VERSION "..\..\trunk\components\winTestMT\code\canApi\dbcFiles\canBus_02.dbc, created by Octave and generateRandomDbc.m on 21-Feb-2017"

NS_ :

BS_:

BU_: ECU

BO_ 90 frame_90: 8 Vector__XXX
  SG_ checksum_1_8 : 0|8@1+ (1.0,0.0) [0.0|255.0] "" ECU
  SG_ sig_16_36 : 16|36@1+ (1.0000000000000007E-7,-3162.2776601683795) [-3162.2776601683795|3709.670013231626] "kWh" ECU
  SG_ sig_15_7 : 15|7@0- (100.0,3162.2776601683795) [-3237.7223398316205|9362.27766016838] "A" ECU
  SG_ sig_8_1 : 8|1@1+ (1.0,0.0) [0.0|1.0] "" ECU
  SG_ sig_52_10 : 52|10@1+ (1.0000000000000005E-4,0.0) [0.0|0.10220000000000004] "V" ECU

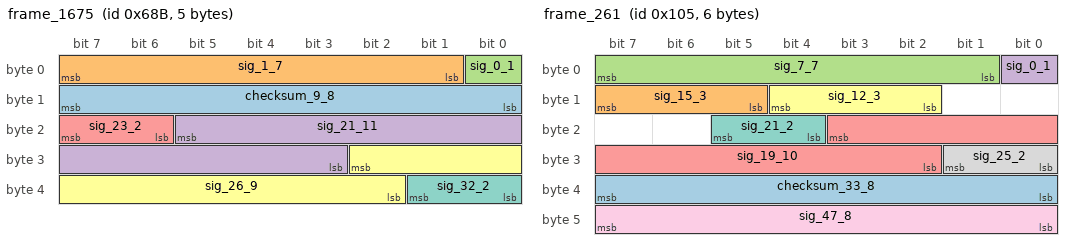
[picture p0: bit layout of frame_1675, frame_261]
BO_ 1675 frame_1675: 5 Vector__XXX
  SG_ checksum_9_8 : 15|8@0+ (1.0,0.0) [0.0|255.0] "" ECU
  SG_ sig_1_7 : 1|7@1+ (0.010000000000000002,0.31622776601683794) [0.31622776601683794|1.5762277660168382] "kWh" ECU
  SG_ sig_0_1 : 0|1@1+ (1.0,0.0) [0.0|1.0] "" ECU
  SG_ sig_21_11 : 21|11@0- (100.0,-31622.776601683792) [-134022.77660168378|70577.22339831622] "A" ECU
  SG_ sig_23_2 : 23|2@0+ (1.0,0.0) [0.0|3.0] "" ECU
  SG_ sig_26_9 : 26|9@0- (1.0000000000000005E-4,0.03162277660168379) [0.00602277660168378|0.057022776601683804] "A" ECU
  SG_ sig_32_2 : 32|2@1+ (1.0,0.0) [0.0|3.0] "" ECU

BO_ 261 frame_261: 6 Vector__XXX
  SG_ checksum_33_8 : 39|8@0+ (1.0,0.0) [0.0|255.0] "" ECU
  SG_ sig_15_3 : 15|3@0+ (1.0,0.0) [0.0|6.0] "" ECU
  SG_ sig_7_7 : 7|7@0+ (1.0,0.0) [0.0|126.0] "" ECU
  SG_ sig_0_1 : 0|1@0+ (1.0,0.0) [0.0|1.0] "" ECU
  SG_ sig_19_10 : 19|10@0+ (1.0000000000000006E-5,0.0031622776601683794) [0.0031622776601683794|0.013382277660168387] "A" ECU
  SG_ sig_12_3 : 12|3@0+ (1.0,0.0) [0.0|6.0] "" ECU
  SG_ sig_21_2 : 21|2@0+ (1.0,0.0) [0.0|3.0] "" ECU
  SG_ sig_25_2 : 25|2@0+ (1.0,0.0) [0.0|3.0] "" ECU
  SG_ sig_47_8 : 47|8@0+ (1.0000000000000005E-4,0.0) [0.0|0.025400000000000013] "W" ECU

BO_ 660 frame_660: 4 Vector__XXX
  SG_ checksum_9_8 : 8|8@1+ (1.0,0.0) [0.0|255.0] "" ECU
  SG_ sig_0_8 : 0|8@1+ (1.0000000000000007E-7,3.162277660168379E-6) [3.162277660168379E-6|2.85622776601684E-5] "kWh" ECU
  SG_ sig_17_14 : 17|14@1+ (1.0000000000000006E-5,0.0) [0.0|0.1638200000000001] "s" ECU
  SG_ sig_16_1 : 16|1@1+ (1.0,0.0) [0.0|1.0] "" ECU
  SG_ sig_31_1 : 31|1@1+ (1.0,0.0) [0.0|1.0] "" ECU

BO_ 1074 frame_1074: 6 Vector__XXX
  SG_ checksum_25_8 : 31|8@0+ (1.0,0.0) [0.0|255.0] "" ECU
  SG_ sig_7_22 : 7|22@0+ (1.0000000000000006E-6,0.0) [0.0|4.194302000000002] "V" ECU
  SG_ sig_17_2 : 17|2@0- (1.0,0.0) [-2.0|1.0] "" ECU
  SG_ sig_37_14 : 37|14@0+ (0.010000000000000002,-31.622776601683793) [-31.622776601683793|132.19722339831623] "A" ECU
  SG_ sig_39_2 : 39|2@0+ (1.0,0.0) [0.0|3.0] "" ECU

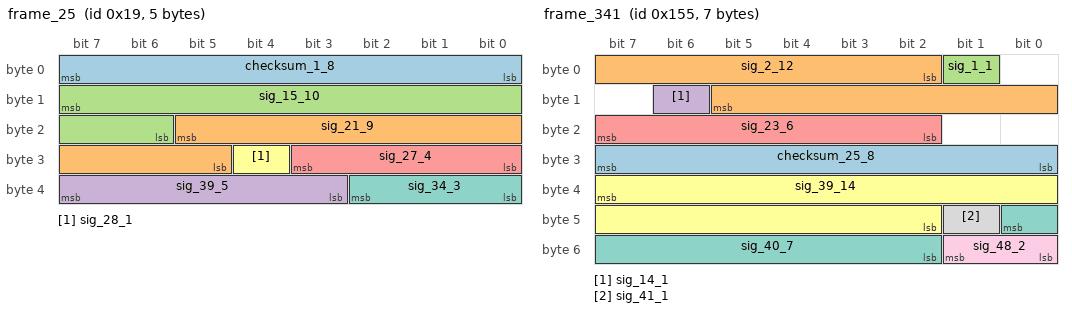
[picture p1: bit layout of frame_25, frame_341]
BO_ 25 frame_25: 5 ECU
  SG_ checksum_1_8 : 7|8@0+ (1.0,0.0) [0.0|255.0] "" Vector__XXX
  SG_ sig_21_9 : 21|9@0+ (1.0,0.0) [0.0|510.0] "" Vector__XXX
  SG_ sig_15_10 : 15|10@0- (1.0,-316.22776601683796) [-828.2277660168379|193.77223398316204] "m/s^2" Vector__XXX
  SG_ sig_39_5 : 39|5@0- (1.0,0.0) [-16.0|14.0] "" Vector__XXX
  SG_ sig_27_4 : 27|4@0- (100.0,316.22776601683796) [-483.77223398316204|916.2277660168379] "A" Vector__XXX
  SG_ sig_28_1 : 28|1@0+ (1.0,0.0) [0.0|1.0] "" Vector__XXX
  SG_ sig_34_3 : 34|3@0+ (1.0,0.0) [0.0|6.0] "" Vector__XXX

BO_ 1747 frame_1747: 8 Vector__XXX
  SG_ checksum_17_8 : 23|8@0+ (1.0,0.0) [0.0|255.0] "" ECU
  SG_ sig_5_14 : 5|14@0+ (1.0,0.0) [0.0|16382.0] "" ECU
  SG_ sig_6_2 : 6|2@1+ (1.0,0.0) [0.0|3.0] "" ECU
  SG_ sig_26_28 : 26|28@0- (1.0000000000000006E-6,31.622776601683793) [-102.59495139831628|165.84050260168388] "m/s^2" ECU
  SG_ sig_31_5 : 31|5@0+ (1.0,0.0) [0.0|30.0] "" ECU
  SG_ sig_62_7 : 62|7@0- (1000.0,-31622.776601683792) [-95622.77660168378|30377.223398316208] "kWh" ECU

BO_ 1641 frame_1641: 5 ECU
  SG_ checksum_25_8 : 31|8@0+ (1.0,0.0) [0.0|255.0] "" Vector__XXX
  SG_ sig_5_15 : 5|15@1+ (1.0000000000000007E-7,0.0) [0.0|0.0032766000000000023] "s" Vector__XXX
  SG_ sig_4_5 : 4|5@0+ (1.0000000000000005E-4,0.0) [0.0|0.0030000000000000014] "A" Vector__XXX
  SG_ sig_23_1 : 23|1@0+ (1.0,0.0) [0.0|1.0] "" Vector__XXX
  SG_ sig_32_8 : 32|8@1- (1.0000000000000005E-4,0.0031622776601683794) [-0.009637722339831626|0.015762277660168383] "A" Vector__XXX

BO_ 786 frame_786: 4 Vector__XXX
  SG_ checksum_1_8 : 7|8@0+ (1.0,0.0) [0.0|255.0] "" ECU
  SG_ sig_20_9 : 20|9@0+ (1.0000000000000006E-5,0.0031622776601683794) [0.0031622776601683794|0.008262277660168382] "km/h" ECU
  SG_ sig_15_8 : 15|8@0- (1.0,0.0) [-128.0|126.0] "" ECU
  SG_ sig_22_2 : 22|2@0- (1.0,0.0) [-2.0|1.0] "" ECU
  SG_ sig_23_1 : 23|1@0+ (1.0,0.0) [0.0|1.0] "" ECU
  SG_ sig_27_4 : 27|4@0- (0.0010000000000000002,0.0031622776601683794) [-0.004837722339831622|0.009162277660168382] "A" ECU

BO_ 341 frame_341: 7 Vector__XXX
  SG_ checksum_25_8 : 24|8@1+ (1.0,0.0) [0.0|255.0] "" ECU
  SG_ sig_2_12 : 2|12@1- (1.0000000000000009E-9,-3.162277660168379E-6) [-5.210277660168381E-6|-1.1162776601683775E-6] "W" ECU
  SG_ sig_1_1 : 1|1@0+ (1.0,0.0) [0.0|1.0] "" ECU
  SG_ sig_14_1 : 14|1@0+ (1.0,0.0) [0.0|1.0] "" ECU
  SG_ sig_23_6 : 23|6@0- (1.0000000000000005E-4,0.0) [-0.0032000000000000015|0.0030000000000000014] "km/h" ECU
  SG_ sig_39_14 : 39|14@0- (1.0000000000000005E-4,-0.31622776601683794) [-1.1354277660168384|0.5027722339831624] "kWh" ECU
  SG_ sig_40_7 : 40|7@0- (1.0,0.0) [-64.0|62.0] "" ECU
  SG_ sig_41_1 : 41|1@0+ (1.0,0.0) [0.0|1.0] "" ECU
  SG_ sig_48_2 : 48|2@1- (1.0,0.0) [-2.0|1.0] "" ECU

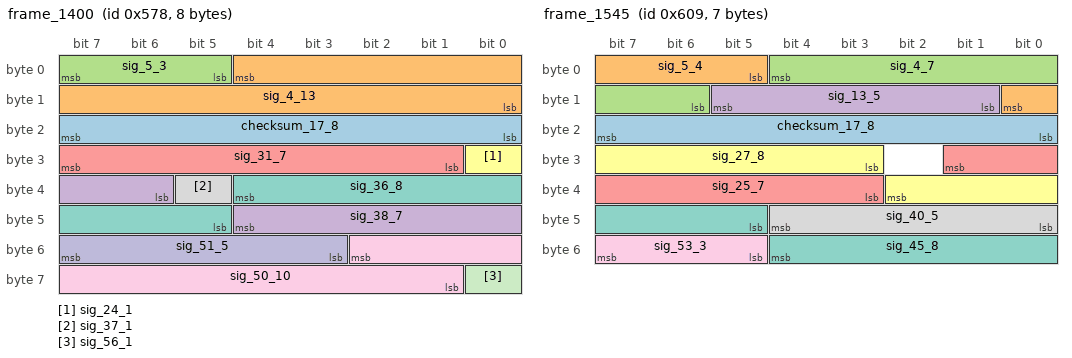
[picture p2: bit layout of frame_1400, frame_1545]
BO_ 1400 frame_1400: 8 Vector__XXX
  SG_ checksum_17_8 : 16|8@1+ (1.0,0.0) [0.0|255.0] "" ECU
  SG_ sig_4_13 : 4|13@0+ (1.0,0.0) [0.0|8190.0] "" ECU
  SG_ sig_5_3 : 5|3@1- (1.0,0.0) [-4.0|2.0] "" ECU
  SG_ sig_38_7 : 38|7@1+ (1.0000000000000006E-5,3.1622776601683794E-4) [3.1622776601683794E-4|0.0015762277660168386] "kWh" ECU
  SG_ sig_31_7 : 31|7@0+ (1.0,0.0) [0.0|126.0] "" ECU
  SG_ sig_24_1 : 24|1@1+ (1.0,0.0) [0.0|1.0] "" ECU
  SG_ sig_36_8 : 36|8@0+ (1.0,0.0) [0.0|254.0] "" ECU
  SG_ sig_37_1 : 37|1@1+ (1.0,0.0) [0.0|1.0] "" ECU
  SG_ sig_50_10 : 50|10@0+ (1.0000000000000005E-4,-0.03162277660168379) [-0.03162277660168379|0.07057722339831625] "A" ECU
  SG_ sig_51_5 : 51|5@1- (100.0,0.0) [-1600.0|1400.0] "W" ECU
  SG_ sig_56_1 : 56|1@0+ (1.0,0.0) [0.0|1.0] "" ECU

BO_ 1545 frame_1545: 7 Vector__XXX
  SG_ checksum_17_8 : 23|8@0+ (1.0,0.0) [0.0|255.0] "" ECU
  SG_ sig_5_4 : 5|4@1- (10000.0,0.0) [-80000.0|60000.0] "kWh" ECU
  SG_ sig_4_7 : 4|7@0+ (1.0,0.0) [0.0|126.0] "" ECU
  SG_ sig_13_5 : 13|5@0+ (1.0000000000000007E-7,-3.162277660168379E-6) [-3.162277660168379E-6|-1.62277660168377E-7] "V" ECU
  SG_ sig_25_7 : 25|7@0+ (1.0000000000000006E-5,0.0) [0.0|0.0012600000000000007] "km/h" ECU
  SG_ sig_27_8 : 27|8@1+ (1.0000000000000005E-4,-0.0031622776601683794) [-0.0031622776601683794|0.022237722339831633] "W" ECU
  SG_ sig_45_8 : 45|8@1- (1.0,0.0) [-128.0|126.0] "" ECU
  SG_ sig_40_5 : 40|5@1- (0.010000000000000002,0.0) [-0.16000000000000003|0.14] "kWh" ECU
  SG_ sig_53_3 : 53|3@1+ (1.0,0.0) [0.0|6.0] "" ECU

BO_ 669 frame_669: 6 ECU
  SG_ checksum_25_8 : 24|8@1+ (1.0,0.0) [0.0|255.0] "" Vector__XXX
  SG_ sig_7_17 : 7|17@0- (0.1,3162.2776601683795) [-3391.322339831621|9715.67766016838] "s" Vector__XXX
  SG_ sig_16_6 : 16|6@1+ (1.0000000000000005E-4,-0.0031622776601683794) [-0.0031622776601683794|0.003037722339831623] "V" Vector__XXX
  SG_ sig_22_1 : 22|1@0+ (1.0,0.0) [0.0|1.0] "" Vector__XXX
  SG_ sig_38_15 : 38|15@0+ (1.0,0.0) [0.0|32766.0] "" Vector__XXX

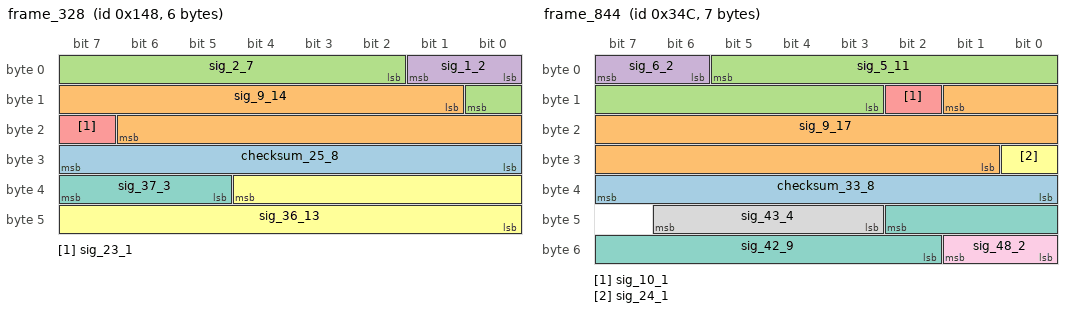
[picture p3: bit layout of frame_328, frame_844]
BO_ 328 frame_328: 6 Vector__XXX
  SG_ checksum_25_8 : 31|8@0+ (1.0,0.0) [0.0|255.0] "" ECU
  SG_ sig_9_14 : 9|14@1- (1.0000000000000008E-8,0.0) [-8.192000000000007E-5|8.190000000000007E-5] "V" ECU
  SG_ sig_2_7 : 2|7@1- (1.0000000000000005E-4,0.0031622776601683794) [-0.0032377223398316235|0.009362277660168382] "s" ECU
  SG_ sig_1_2 : 1|2@0+ (1.0,0.0) [0.0|3.0] "" ECU
  SG_ sig_23_1 : 23|1@1+ (1.0,0.0) [0.0|1.0] "" ECU
  SG_ sig_36_13 : 36|13@0- (1.0,0.0) [-4096.0|4094.0] "" ECU
  SG_ sig_37_3 : 37|3@1- (1.0,0.0) [-4.0|2.0] "" ECU

BO_ 844 frame_844: 7 Vector__XXX
  SG_ checksum_33_8 : 39|8@0+ (1.0,0.0) [0.0|255.0] "" ECU
  SG_ sig_9_17 : 9|17@0- (0.1,-3162.2776601683795) [-9715.87766016838|3391.122339831621] "kWh" ECU
  SG_ sig_5_11 : 5|11@0- (0.1,0.0) [-102.4|102.2] "s" ECU
  SG_ sig_6_2 : 6|2@1- (1.0,0.0) [-2.0|1.0] "" ECU
  SG_ sig_10_1 : 10|1@1+ (1.0,0.0) [0.0|1.0] "" ECU
  SG_ sig_24_1 : 24|1@0+ (1.0,0.0) [0.0|1.0] "" ECU
  SG_ sig_42_9 : 42|9@0+ (1.0000000000000005E-4,-0.03162277660168379) [-0.03162277660168379|0.019377223398316233] "V" ECU
  SG_ sig_43_4 : 43|4@1- (1.0,0.0) [-8.0|6.0] "" ECU
  SG_ sig_48_2 : 48|2@1- (1.0,0.0) [-2.0|1.0] "" ECU

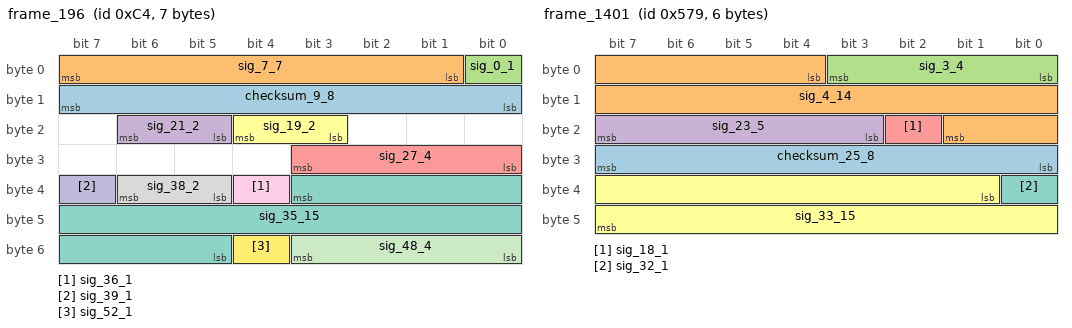
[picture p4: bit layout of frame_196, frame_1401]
BO_ 196 frame_196: 7 Vector__XXX
  SG_ checksum_9_8 : 8|8@1+ (1.0,0.0) [0.0|255.0] "" ECU
  SG_ sig_7_7 : 7|7@0- (1.0,0.0) [-64.0|62.0] "" ECU
  SG_ sig_0_1 : 0|1@1+ (1.0,0.0) [0.0|1.0] "" ECU
  SG_ sig_21_2 : 21|2@1+ (1.0,0.0) [0.0|3.0] "" ECU
  SG_ sig_27_4 : 27|4@0- (100.0,316.22776601683796) [-483.77223398316204|916.2277660168379] "s" ECU
  SG_ sig_19_2 : 19|2@1- (1.0,0.0) [-2.0|1.0] "" ECU
  SG_ sig_35_15 : 35|15@0+ (1.0,-31622.776601683792) [-31622.776601683792|1143.2233983162077] "m/s^2" ECU
  SG_ sig_38_2 : 38|2@0+ (1.0,0.0) [0.0|3.0] "" ECU
  SG_ sig_36_1 : 36|1@1+ (1.0,0.0) [0.0|1.0] "" ECU
  SG_ sig_39_1 : 39|1@1+ (1.0,0.0) [0.0|1.0] "" ECU
  SG_ sig_48_4 : 48|4@1+ (1.0,0.0) [0.0|14.0] "" ECU
  SG_ sig_52_1 : 52|1@1+ (1.0,0.0) [0.0|1.0] "" ECU

BO_ 870 frame_870: 5 Vector__XXX
  SG_ checksum_9_8 : 15|8@0+ (1.0,0.0) [0.0|255.0] "" ECU
  SG_ sig_1_7 : 1|7@1- (0.0010000000000000002,0.03162277660168379) [-0.032377223398316224|0.0936227766016838] "m/s^2" ECU
  SG_ sig_0_1 : 0|1@0+ (1.0,0.0) [0.0|1.0] "" ECU
  SG_ sig_17_20 : 17|20@1+ (0.1,-31622.776601683792) [-31622.776601683792|73234.62339831621] "A" ECU
  SG_ sig_37_3 : 37|3@1- (1.0,0.0) [-4.0|2.0] "" ECU

BO_ 1492 frame_1492: 5 Vector__XXX
  SG_ checksum_9_8 : 15|8@0+ (1.0,0.0) [0.0|255.0] "" ECU
  SG_ sig_7_7 : 7|7@0- (1.0000000000000006E-5,0.0) [-6.400000000000004E-4|6.200000000000003E-4] "V" ECU
  SG_ sig_0_1 : 0|1@0+ (1.0,0.0) [0.0|1.0] "" ECU
  SG_ sig_32_7 : 32|7@1+ (1.0,0.0) [0.0|126.0] "" ECU
  SG_ sig_16_10 : 16|10@0- (1.0,316.22776601683796) [-195.77223398316204|826.2277660168379] "m/s^2" ECU
  SG_ sig_17_7 : 17|7@1- (100.0,3162.2776601683795) [-3237.7223398316205|9362.27766016838] "km/h" ECU

BO_ 1401 frame_1401: 6 ECU
  SG_ checksum_25_8 : 31|8@0+ (1.0,0.0) [0.0|255.0] "" Vector__XXX
  SG_ sig_4_14 : 4|14@1+ (1.0000000000000005E-4,-0.31622776601683794) [-0.31622776601683794|1.3219722339831628] "km/h" Vector__XXX
  SG_ sig_3_4 : 3|4@0- (1.0,0.0) [-8.0|6.0] "" Vector__XXX
  SG_ sig_23_5 : 23|5@0- (1.0000000000000005E-4,-0.0031622776601683794) [-0.0047622776601683806|-0.0017622776601683788] "kWh" Vector__XXX
  SG_ sig_18_1 : 18|1@1+ (1.0,0.0) [0.0|1.0] "" Vector__XXX
  SG_ sig_33_15 : 33|15@1+ (1.0000000000000008E-8,0.0) [0.0|3.276600000000003E-4] "W" Vector__XXX
  SG_ sig_32_1 : 32|1@1+ (1.0,0.0) [0.0|1.0] "" Vector__XXX

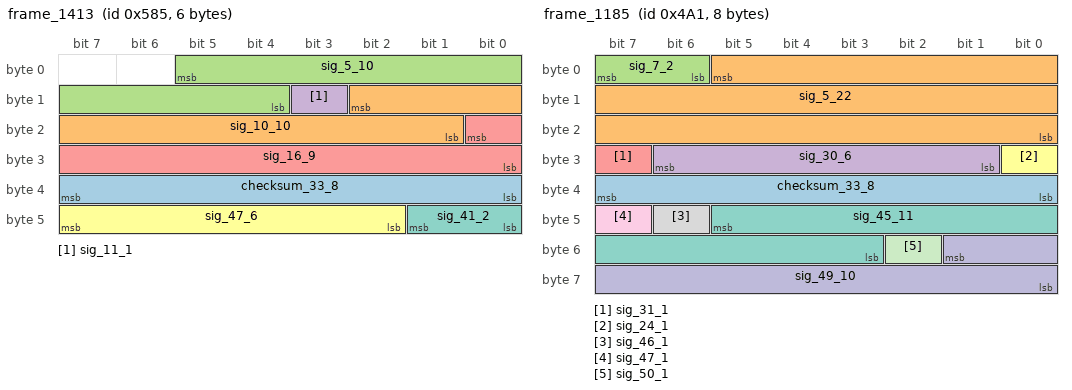
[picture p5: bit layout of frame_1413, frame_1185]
BO_ 1413 frame_1413: 6 Vector__XXX
  SG_ checksum_33_8 : 39|8@0+ (1.0,0.0) [0.0|255.0] "" ECU
  SG_ sig_10_10 : 10|10@0- (1.0000000000000006E-6,3.1622776601683794E-4) [-1.9577223398316236E-4|8.262277660168382E-4] "s" ECU
  SG_ sig_5_10 : 5|10@0+ (1.0,0.0) [0.0|1022.0] "" ECU
  SG_ sig_11_1 : 11|1@0+ (1.0,0.0) [0.0|1.0] "" ECU
  SG_ sig_16_9 : 16|9@0- (10.0,3162.2776601683795) [602.2776601683795|5702.27766016838] "kWh" ECU
  SG_ sig_47_6 : 47|6@0+ (1.0000000000000006E-5,0.0) [0.0|6.200000000000003E-4] "A" ECU
  SG_ sig_41_2 : 41|2@0- (1.0,0.0) [-2.0|1.0] "" ECU

BO_ 1185 frame_1185: 8 Vector__XXX
  SG_ checksum_33_8 : 39|8@0+ (1.0,0.0) [0.0|255.0] "" ECU
  SG_ sig_5_22 : 5|22@0+ (1.0000000000000011E-10,-3.1622776601683794E-4) [-3.1622776601683794E-4|1.032024339831625E-4] "s" ECU
  SG_ sig_7_2 : 7|2@0- (1.0,0.0) [-2.0|1.0] "" ECU
  SG_ sig_30_6 : 30|6@0- (1.0,0.0) [-32.0|30.0] "" ECU
  SG_ sig_31_1 : 31|1@0+ (1.0,0.0) [0.0|1.0] "" ECU
  SG_ sig_24_1 : 24|1@0+ (1.0,0.0) [0.0|1.0] "" ECU
  SG_ sig_45_11 : 45|11@0- (0.010000000000000002,0.0) [-10.240000000000002|10.220000000000002] "km/h" ECU
  SG_ sig_46_1 : 46|1@0+ (1.0,0.0) [0.0|1.0] "" ECU
  SG_ sig_47_1 : 47|1@0+ (1.0,0.0) [0.0|1.0] "" ECU
  SG_ sig_49_10 : 49|10@0+ (1.0000000000000006E-5,-0.0031622776601683794) [-0.0031622776601683794|0.007057722339831627] "m/s^2" ECU
  SG_ sig_50_1 : 50|1@0+ (1.0,0.0) [0.0|1.0] "" ECU

BO_ 322 frame_322: 8 Vector__XXX
  SG_ checksum_41_8 : 40|8@1+ (1.0,0.0) [0.0|255.0] "" ECU
  SG_ sig_11_23 : 11|23@1- (1.0000000000000014E-12,0.0) [-4.194304000000006E-6|4.194302000000006E-6] "km/h" ECU
  SG_ sig_7_8 : 7|8@0- (1.0000000000000006E-6,-3.1622776601683795E-5) [-1.5962277660168386E-4|9.437722339831629E-5] "s" ECU
  SG_ sig_8_3 : 8|3@1+ (1.0,0.0) [0.0|6.0] "" ECU
  SG_ sig_36_2 : 36|2@1+ (1.0,0.0) [0.0|3.0] "" ECU
  SG_ sig_39_2 : 39|2@0+ (1.0,0.0) [0.0|3.0] "" ECU
  SG_ sig_55_16 : 55|16@0- (1.0000000000000007E-7,0.0031622776601683794) [-1.1452233983162306E-4|0.006438877660168382] "V" ECU

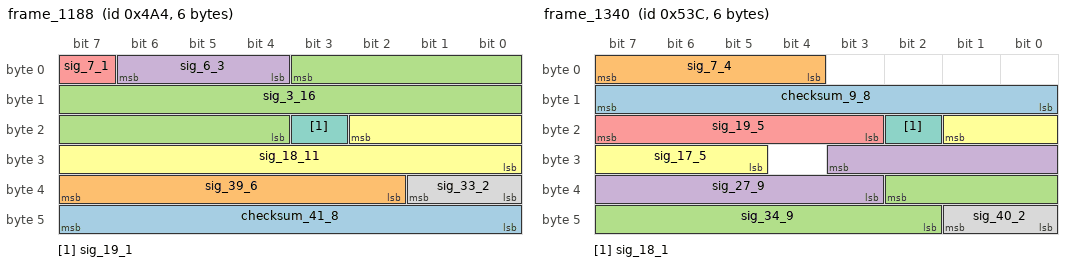
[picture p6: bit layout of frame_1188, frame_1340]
BO_ 1188 frame_1188: 6 Vector__XXX
  SG_ checksum_41_8 : 47|8@0+ (1.0,0.0) [0.0|255.0] "" ECU
  SG_ sig_39_6 : 39|6@0+ (1.0,0.0) [0.0|62.0] "" ECU
  SG_ sig_3_16 : 3|16@0+ (0.010000000000000002,0.0) [0.0|655.3400000000001] "m/s^2" ECU
  SG_ sig_6_3 : 6|3@0+ (1.0,0.0) [0.0|6.0] "" ECU
  SG_ sig_7_1 : 7|1@0+ (1.0,0.0) [0.0|1.0] "" ECU
  SG_ sig_18_11 : 18|11@0+ (1.0000000000000006E-5,0.0) [0.0|0.020460000000000013] "A" ECU
  SG_ sig_19_1 : 19|1@0+ (1.0,0.0) [0.0|1.0] "" ECU
  SG_ sig_33_2 : 33|2@0+ (1.0,0.0) [0.0|3.0] "" ECU

BO_ 1340 frame_1340: 6 ECU
  SG_ checksum_9_8 : 15|8@0+ (1.0,0.0) [0.0|255.0] "" Vector__XXX
  SG_ sig_7_4 : 7|4@0- (1.0,0.0) [-8.0|6.0] "" Vector__XXX
  SG_ sig_34_9 : 34|9@0- (10.0,3162.2776601683795) [602.2776601683795|5702.27766016838] "m/s^2" Vector__XXX
  SG_ sig_27_9 : 27|9@0+ (100.0,-31622.776601683792) [-31622.776601683792|19377.223398316208] "s" Vector__XXX
  SG_ sig_19_5 : 19|5@1+ (10.0,-316.22776601683796) [-316.22776601683796|-16.22776601683796] "A" Vector__XXX
  SG_ sig_17_5 : 17|5@0- (1.0,31.622776601683793) [15.622776601683793|45.622776601683796] "m/s^2" Vector__XXX
  SG_ sig_18_1 : 18|1@0+ (1.0,0.0) [0.0|1.0] "" Vector__XXX
  SG_ sig_40_2 : 40|2@1- (1.0,0.0) [-2.0|1.0] "" Vector__XXX

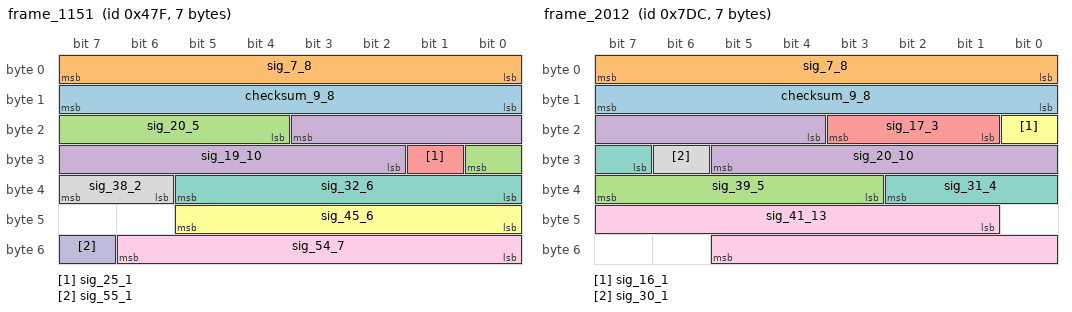
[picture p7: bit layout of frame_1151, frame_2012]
BO_ 1151 frame_1151: 7 ECU
  SG_ checksum_9_8 : 8|8@1+ (1.0,0.0) [0.0|255.0] "" Vector__XXX
  SG_ sig_7_8 : 7|8@0+ (1.0,0.0) [0.0|254.0] "" Vector__XXX
  SG_ sig_20_5 : 20|5@1+ (1.0,0.0) [0.0|30.0] "" Vector__XXX
  SG_ sig_19_10 : 19|10@0- (1.0,0.0) [-512.0|510.0] "" Vector__XXX
  SG_ sig_25_1 : 25|1@1+ (1.0,0.0) [0.0|1.0] "" Vector__XXX
  SG_ sig_45_6 : 45|6@0+ (1.0,0.0) [0.0|62.0] "" Vector__XXX
  SG_ sig_32_6 : 32|6@1- (1.0,0.0) [-32.0|30.0] "" Vector__XXX
  SG_ sig_38_2 : 38|2@1- (1.0,0.0) [-2.0|1.0] "" Vector__XXX
  SG_ sig_54_7 : 54|7@0- (100.0,3162.2776601683795) [-3237.7223398316205|9362.27766016838] "m/s^2" Vector__XXX
  SG_ sig_55_1 : 55|1@0+ (1.0,0.0) [0.0|1.0] "" Vector__XXX

BO_ 2012 frame_2012: 7 Vector__XXX
  SG_ checksum_9_8 : 15|8@0+ (1.0,0.0) [0.0|255.0] "" ECU
  SG_ sig_7_8 : 7|8@0+ (1.0,-31.622776601683793) [-31.622776601683793|222.3772233983162] "m/s^2" ECU
  SG_ sig_39_5 : 39|5@0+ (10.0,0.0) [0.0|300.0] "s" ECU
  SG_ sig_20_10 : 20|10@1- (0.1,0.0) [-51.2|51.0] "m/s^2" ECU
  SG_ sig_17_3 : 17|3@1- (1.0,0.0) [-4.0|2.0] "" ECU
  SG_ sig_16_1 : 16|1@1+ (1.0,0.0) [0.0|1.0] "" ECU
  SG_ sig_31_4 : 31|4@1+ (1.0000000000000006E-6,3.162277660168379E-6) [3.162277660168379E-6|1.7162277660168386E-5] "km/h" ECU
  SG_ sig_30_1 : 30|1@0+ (1.0,0.0) [0.0|1.0] "" ECU
  SG_ sig_41_13 : 41|13@1+ (1.0000000000000009E-9,-3.162277660168379E-6) [-3.162277660168379E-6|5.027722339831629E-6] "s" ECU

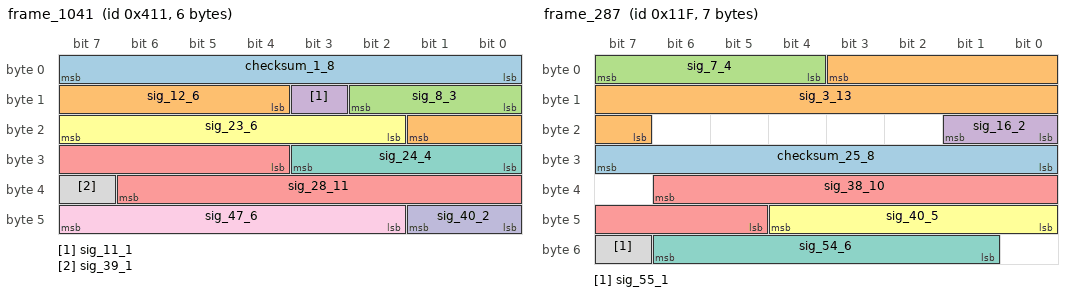
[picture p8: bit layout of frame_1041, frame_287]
BO_ 1041 frame_1041: 6 Vector__XXX
  SG_ checksum_1_8 : 0|8@1+ (1.0,0.0) [0.0|255.0] "" ECU
  SG_ sig_12_6 : 12|6@1+ (1.0,0.0) [0.0|62.0] "" ECU
  SG_ sig_8_3 : 8|3@1+ (1.0,0.0) [0.0|6.0] "" ECU
  SG_ sig_11_1 : 11|1@0+ (1.0,0.0) [0.0|1.0] "" ECU
  SG_ sig_28_11 : 28|11@1- (100.0,31622.776601683792) [-70777.22339831622|133822.77660168378] "A" ECU
  SG_ sig_23_6 : 23|6@0- (1.0,0.0) [-32.0|30.0] "" ECU
  SG_ sig_24_4 : 24|4@1+ (0.010000000000000002,-0.03162277660168379) [-0.03162277660168379|0.10837722339831622] "m/s^2" ECU
  SG_ sig_39_1 : 39|1@0+ (1.0,0.0) [0.0|1.0] "" ECU
  SG_ sig_47_6 : 47|6@0- (1.0000000000000006E-6,0.0) [-3.200000000000002E-5|3.0000000000000018E-5] "V" ECU
  SG_ sig_40_2 : 40|2@1- (1.0,0.0) [-2.0|1.0] "" ECU

BO_ 287 frame_287: 7 Vector__XXX
  SG_ checksum_25_8 : 24|8@1+ (1.0,0.0) [0.0|255.0] "" ECU
  SG_ sig_3_13 : 3|13@0- (0.010000000000000002,31.622776601683793) [-9.337223398316215|72.5627766016838] "km/h" ECU
  SG_ sig_7_4 : 7|4@0+ (1.0,0.0) [0.0|14.0] "" ECU
  SG_ sig_16_2 : 16|2@1- (1.0,0.0) [-2.0|1.0] "" ECU
  SG_ sig_38_10 : 38|10@0+ (1.0,-316.22776601683796) [-316.22776601683796|705.7722339831621] "s" ECU
  SG_ sig_40_5 : 40|5@1+ (1.0,0.0) [0.0|30.0] "" ECU
  SG_ sig_54_6 : 54|6@0+ (1.0000000000000006E-5,3.1622776601683794E-4) [3.1622776601683794E-4|9.362277660168383E-4] "W" ECU
  SG_ sig_55_1 : 55|1@0+ (1.0,0.0) [0.0|1.0] "" ECU

BO_ 138 frame_138: 6 Vector__XXX
  SG_ checksum_1_8 : 0|8@1+ (1.0,0.0) [0.0|255.0] "" ECU
  SG_ sig_27_21 : 27|21@1+ (0.1,31622.776601683792) [31622.776601683792|241337.77660168378] "V" ECU
  SG_ sig_8_1 : 8|1@1+ (1.0,0.0) [0.0|1.0] "" ECU

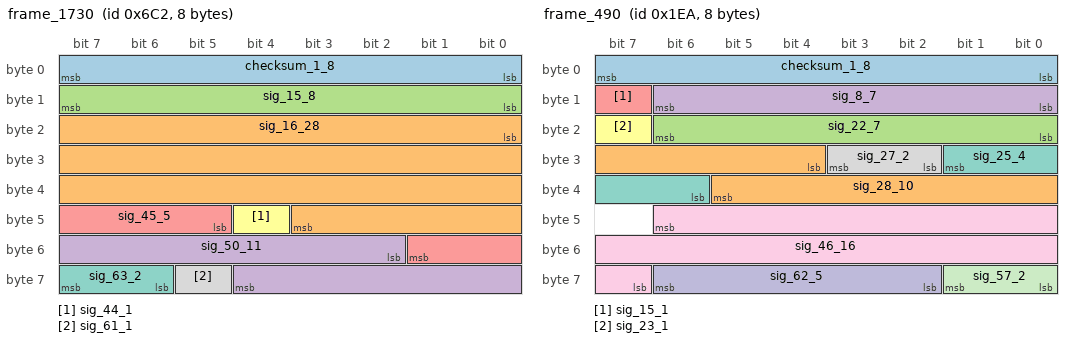
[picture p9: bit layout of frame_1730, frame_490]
BO_ 1730 frame_1730: 8 ECU
  SG_ checksum_1_8 : 0|8@1+ (1.0,0.0) [0.0|255.0] "" Vector__XXX
  SG_ sig_16_28 : 16|28@1- (1.000000000000001E-11,0.0) [-0.0013421772800000014|0.0013421772600000015] "s" Vector__XXX
  SG_ sig_15_8 : 15|8@0- (1000.0,-31622.776601683792) [-159622.77660168378|94377.22339831622] "W" Vector__XXX
  SG_ sig_50_11 : 50|11@1- (1.0000000000000006E-5,0.0) [-0.010240000000000006|0.010220000000000007] "V" Vector__XXX
  SG_ sig_45_5 : 45|5@1- (1000.0,0.0) [-16000.0|14000.0] "km/h" Vector__XXX
  SG_ sig_44_1 : 44|1@1+ (1.0,0.0) [0.0|1.0] "" Vector__XXX
  SG_ sig_63_2 : 63|2@0- (1.0,0.0) [-2.0|1.0] "" Vector__XXX
  SG_ sig_61_1 : 61|1@0+ (1.0,0.0) [0.0|1.0] "" Vector__XXX

BO_ 937 frame_937: 6 Vector__XXX
  SG_ checksum_1_8 : 0|8@1+ (1.0,0.0) [0.0|255.0] "" ECU
  SG_ sig_10_33 : 10|33@1- (1.0000000000000006E-5,-31622.776601683792) [-74572.44956168381|11326.896338316234] "m/s^2" ECU
  SG_ sig_8_2 : 8|2@1- (1.0,0.0) [-2.0|1.0] "" ECU
  SG_ sig_43_5 : 43|5@1+ (1.0000000000000005E-4,-0.0031622776601683794) [-0.0031622776601683794|-1.6227766016837803E-4] "kWh" ECU

BO_ 490 frame_490: 8 Vector__XXX
  SG_ checksum_1_8 : 0|8@1+ (1.0,0.0) [0.0|255.0] "" ECU
  SG_ sig_28_10 : 28|10@1- (1.0000000000000006E-5,-0.0031622776601683794) [-0.008282277660168383|0.0019377223398316236] "s" ECU
  SG_ sig_22_7 : 22|7@0- (1.0,0.0) [-64.0|62.0] "" ECU
  SG_ sig_8_7 : 8|7@1- (0.1,3.1622776601683795) [-3.237722339831621|9.36227766016838] "kWh" ECU
  SG_ sig_15_1 : 15|1@0+ (1.0,0.0) [0.0|1.0] "" ECU
  SG_ sig_23_1 : 23|1@0+ (1.0,0.0) [0.0|1.0] "" ECU
  SG_ sig_25_4 : 25|4@0- (10000.0,-31622.776601683792) [-111622.77660168378|28377.223398316208] "km/h" ECU
  SG_ sig_27_2 : 27|2@0+ (1.0,0.0) [0.0|3.0] "" ECU
  SG_ sig_46_16 : 46|16@0+ (1.0000000000000011E-10,3.162277660168379E-6) [3.162277660168379E-6|9.715677660168387E-6] "s" ECU
  SG_ sig_62_5 : 62|5@0+ (1.0,0.0) [0.0|30.0] "" ECU
  SG_ sig_57_2 : 57|2@0+ (1.0,0.0) [0.0|3.0] "" ECU

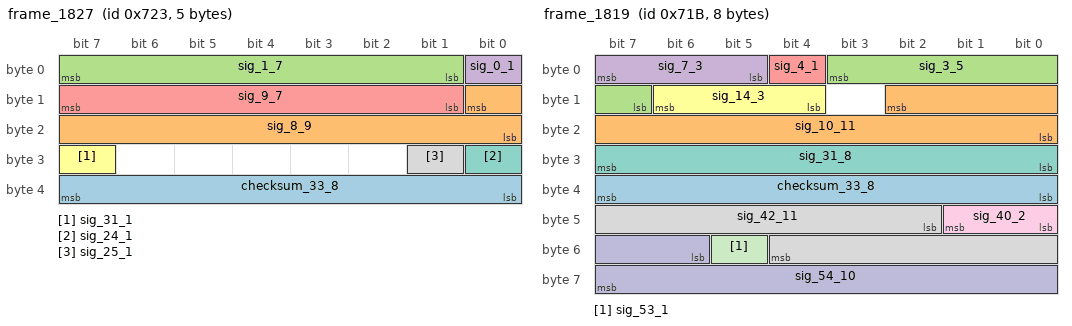
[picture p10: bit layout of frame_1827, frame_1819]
BO_ 1827 frame_1827: 5 Vector__XXX
  SG_ checksum_33_8 : 32|8@1+ (1.0,0.0) [0.0|255.0] "" ECU
  SG_ sig_8_9 : 8|9@0- (1.0,-316.22776601683796) [-572.2277660168379|-62.22776601683796] "A" ECU
  SG_ sig_1_7 : 1|7@1+ (1.0000000000000006E-6,0.0) [0.0|1.2600000000000008E-4] "m/s^2" ECU
  SG_ sig_0_1 : 0|1@1+ (1.0,0.0) [0.0|1.0] "" ECU
  SG_ sig_9_7 : 9|7@1+ (0.010000000000000002,-0.31622776601683794) [-0.31622776601683794|0.9437722339831622] "m/s^2" ECU
  SG_ sig_31_1 : 31|1@0+ (1.0,0.0) [0.0|1.0] "" ECU
  SG_ sig_24_1 : 24|1@0+ (1.0,0.0) [0.0|1.0] "" ECU
  SG_ sig_25_1 : 25|1@0+ (1.0,0.0) [0.0|1.0] "" ECU

BO_ 1819 frame_1819: 8 Vector__XXX
  SG_ checksum_33_8 : 32|8@1+ (1.0,0.0) [0.0|255.0] "" ECU
  SG_ sig_10_11 : 10|11@0+ (1.0000000000000006E-6,0.0) [0.0|0.0020460000000000014] "V" ECU
  SG_ sig_3_5 : 3|5@0+ (1.0000000000000007E-7,3.162277660168379E-6) [3.162277660168379E-6|6.162277660168381E-6] "V" ECU
  SG_ sig_7_3 : 7|3@0+ (1.0,0.0) [0.0|6.0] "" ECU
  SG_ sig_4_1 : 4|1@0+ (1.0,0.0) [0.0|1.0] "" ECU
  SG_ sig_14_3 : 14|3@0+ (1.0,0.0) [0.0|6.0] "" ECU
  SG_ sig_31_8 : 31|8@0- (0.1,3.1622776601683795) [-9.63772233983162|15.762277660168381] "V" ECU
  SG_ sig_42_11 : 42|11@1- (1.0000000000000005E-4,-0.03162277660168379) [-0.13402277660168382|0.07057722339831625] "m/s^2" ECU
  SG_ sig_40_2 : 40|2@1+ (1.0,0.0) [0.0|3.0] "" ECU
  SG_ sig_54_10 : 54|10@1- (1.0000000000000008E-8,0.0) [-5.120000000000004E-6|5.1000000000000045E-6] "m/s^2" ECU
  SG_ sig_53_1 : 53|1@0+ (1.0,0.0) [0.0|1.0] "" ECU

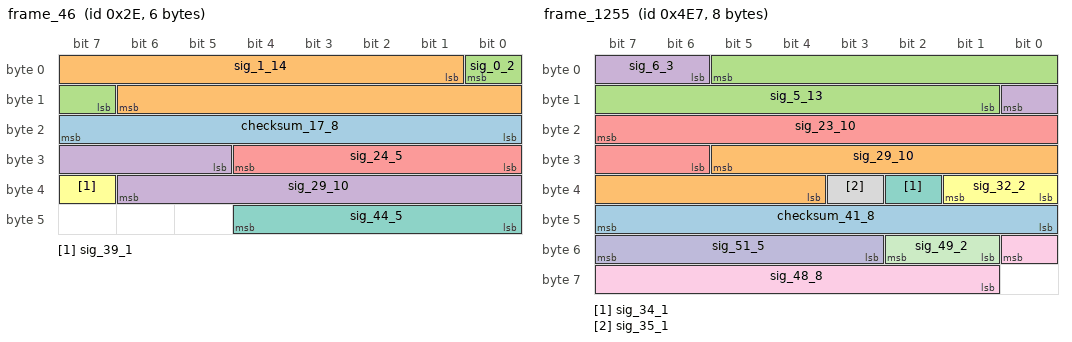
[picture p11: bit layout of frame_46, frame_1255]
BO_ 46 frame_46: 6 ECU
  SG_ checksum_17_8 : 16|8@1+ (1.0,0.0) [0.0|255.0] "" Vector__XXX
  SG_ sig_1_14 : 1|14@1- (1.0000000000000006E-5,0.03162277660168379) [-0.05029722339831626|0.11352277660168383] "kWh" Vector__XXX
  SG_ sig_0_2 : 0|2@0- (1.0,0.0) [-2.0|1.0] "" Vector__XXX
  SG_ sig_29_10 : 29|10@1+ (1.0000000000000007E-7,0.0) [0.0|1.0220000000000007E-4] "W" Vector__XXX
  SG_ sig_24_5 : 24|5@1- (1.0,0.0) [-16.0|14.0] "" Vector__XXX
  SG_ sig_39_1 : 39|1@0+ (1.0,0.0) [0.0|1.0] "" Vector__XXX
  SG_ sig_44_5 : 44|5@0- (1.0,0.0) [-16.0|14.0] "" Vector__XXX

BO_ 1255 frame_1255: 8 Vector__XXX
  SG_ checksum_41_8 : 47|8@0+ (1.0,0.0) [0.0|255.0] "" ECU
  SG_ sig_29_10 : 29|10@0+ (1.0000000000000008E-8,-3.162277660168379E-6) [-3.162277660168379E-6|7.05772233983163E-6] "kWh" ECU
  SG_ sig_5_13 : 5|13@0+ (0.1,316.22776601683796) [316.22776601683796|1135.227766016838] "W" ECU
  SG_ sig_6_3 : 6|3@1- (1.0,0.0) [-4.0|2.0] "" ECU
  SG_ sig_23_10 : 23|10@0+ (0.1,0.0) [0.0|102.2] "km/h" ECU
  SG_ sig_32_2 : 32|2@1- (1.0,0.0) [-2.0|1.0] "" ECU
  SG_ sig_34_1 : 34|1@1+ (1.0,0.0) [0.0|1.0] "" ECU
  SG_ sig_35_1 : 35|1@0+ (1.0,0.0) [0.0|1.0] "" ECU
  SG_ sig_48_8 : 48|8@0- (0.010000000000000002,0.0) [-1.2800000000000002|1.2600000000000002] "V" ECU
  SG_ sig_51_5 : 51|5@1+ (1000.0,0.0) [0.0|30000.0] "m/s^2" ECU
  SG_ sig_49_2 : 49|2@1+ (1.0,0.0) [0.0|3.0] "" ECU

BO_ 1036 frame_1036: 8 Vector__XXX
  SG_ checksum_1_8 : 0|8@1+ (1.0,0.0) [0.0|255.0] "" ECU
  SG_ sig_42_20 : 42|20@1+ (1.0,0.0) [0.0|1048574.0] "" ECU
  SG_ sig_8_20 : 8|20@1+ (1.0000000000000011E-10,-3.1622776601683795E-5) [-3.1622776601683795E-5|7.323462339831632E-5] "kWh" ECU
  SG_ sig_28_12 : 28|12@1- (1.0,0.0) [-2048.0|2046.0] "" ECU
  SG_ sig_40_2 : 40|2@1- (1.0,0.0) [-2.0|1.0] "" ECU
  SG_ sig_63_2 : 63|2@0+ (1.0,0.0) [0.0|3.0] "" ECU

BO_ 1939 frame_1939: 8 ECU
  SG_ checksum_1_8 : 7|8@0+ (1.0,0.0) [0.0|255.0] "" Vector__XXX
  SG_ sig_30_19 : 30|19@0+ (1.0000000000000007E-7,0.0) [0.0|0.05242860000000004] "V" Vector__XXX
  SG_ sig_15_17 : 15|17@0+ (1.0,-31622.776601683792) [-31622.776601683792|99447.22339831622] "kWh" Vector__XXX
  SG_ sig_43_16 : 43|16@0- (1.0000000000000006E-5,0.31622776601683794) [-0.011452233983162252|0.6438877660168381] "W" Vector__XXX
  SG_ sig_58_2 : 58|2@1+ (1.0,0.0) [0.0|3.0] "" Vector__XXX
  SG_ sig_57_2 : 57|2@0+ (1.0,0.0) [0.0|3.0] "" Vector__XXX

BO_ 922 frame_922: 7 Vector__XXX
  SG_ checksum_41_8 : 40|8@1+ (1.0,0.0) [0.0|255.0] "" ECU
  SG_ sig_16_22 : 16|22@1+ (1.0000000000000005E-4,-316.22776601683796) [-316.22776601683796|103.20243398316222] "V" ECU
  SG_ sig_4_9 : 4|9@1+ (10.0,0.0) [0.0|5100.0] "W" ECU
  SG_ sig_0_4 : 0|4@1+ (1.0,0.0) [0.0|14.0] "" ECU
  SG_ sig_38_2 : 38|2@1+ (1.0,0.0) [0.0|3.0] "" ECU
  SG_ sig_49_6 : 49|6@1- (1.0000000000000005E-4,-0.0031622776601683794) [-0.006362277660168381|-1.6227766016837803E-4] "W" ECU
  SG_ sig_48_1 : 48|1@1+ (1.0,0.0) [0.0|1.0] "" ECU

BO_ 759 frame_759: 7 Vector__XXX
  SG_ checksum_49_8 : 48|8@1+ (1.0,0.0) [0.0|255.0] "" ECU
  SG_ sig_5_14 : 5|14@1+ (1.0000000000000007E-7,-3.1622776601683794E-4) [-3.1622776601683794E-4|0.0013219722339831634] "m/s^2" ECU
  SG_ sig_1_4 : 1|4@1- (1.0,0.0) [-8.0|6.0] "" ECU
  SG_ sig_0_1 : 0|1@1+ (1.0,0.0) [0.0|1.0] "" ECU
  SG_ sig_22_14 : 22|14@1+ (1.0,0.0) [0.0|16382.0] "" ECU
  SG_ sig_21_3 : 21|3@0+ (1.0,0.0) [0.0|6.0] "" ECU
  SG_ sig_36_9 : 36|9@1+ (1.0000000000000005E-4,0.0) [0.0|0.051000000000000024] "m/s^2" ECU

BO_ 88 frame_88: 6 Vector__XXX
  SG_ checksum_1_8 : 0|8@1+ (1.0,0.0) [0.0|255.0] "" ECU
  SG_ sig_25_7 : 25|7@0+ (1.0000000000000007E-7,3.162277660168379E-6) [3.162277660168379E-6|1.576227766016839E-5] "km/h" ECU
  SG_ sig_9_8 : 9|8@0+ (1.0,0.0) [0.0|254.0] "" ECU
  SG_ sig_15_6 : 15|6@0- (10.0,-316.22776601683796) [-636.2277660168379|-16.22776601683796] "m/s^2" ECU
  SG_ sig_16_2 : 16|2@1+ (1.0,0.0) [0.0|3.0] "" ECU
  SG_ sig_31_4 : 31|4@0- (1.0,0.0) [-8.0|6.0] "s" ECU
  SG_ sig_47_8 : 47|8@0- (1.0,0.0) [-128.0|126.0] "" ECU

BO_ 162 frame_162: 4 Vector__XXX
  SG_ checksum_17_8 : 16|8@1+ (1.0,0.0) [0.0|255.0] "" ECU
  SG_ sig_2_8 : 2|8@1- (1.0000000000000007E-7,3.162277660168379E-6) [-9.63772233983163E-6|1.576227766016839E-5] "s" ECU
  SG_ sig_0_2 : 0|2@1- (1.0,0.0) [-2.0|1.0] "" ECU
  SG_ sig_10_1 : 10|1@1+ (1.0,0.0) [0.0|1.0] "" ECU
  SG_ sig_29_6 : 29|6@0- (1.0,0.0) [-32.0|30.0] "s" ECU
  SG_ sig_31_2 : 31|2@0- (1.0,0.0) [-2.0|1.0] "" ECU

BO_ 659 frame_659: 6 ECU
  SG_ checksum_41_8 : 47|8@0+ (1.0,0.0) [0.0|255.0] "" Vector__XXX
  SG_ sig_7_19 : 7|19@0- (1.0,0.0) [-262144.0|262142.0] "" Vector__XXX
  SG_ sig_20_3 : 20|3@0+ (1.0,0.0) [0.0|6.0] "" Vector__XXX
  SG_ sig_33_2 : 33|2@0+ (1.0,0.0) [0.0|3.0] "" Vector__XXX

BO_ 495 frame_495: 7 Vector__XXX
  SG_ checksum_17_8 : 16|8@1+ (1.0,0.0) [0.0|255.0] "" ECU
  SG_ sig_1_15 : 1|15@1- (0.1,3162.2776601683795) [1523.8776601683794|4800.47766016838] "A" ECU
  SG_ sig_26_29 : 26|29@1+ (1.0000000000000007E-7,31.622776601683793) [31.622776601683793|85.30986760168383] "kWh" ECU
  SG_ sig_24_2 : 24|2@1+ (1.0,0.0) [0.0|3.0] "" ECU

BO_ 563 frame_563: 6 Vector__XXX
  SG_ checksum_9_8 : 8|8@1+ (1.0,0.0) [0.0|255.0] "" ECU
  SG_ sig_6_7 : 6|7@0- (1.0000000000000005E-4,-0.0031622776601683794) [-0.009562277660168383|0.003037722339831623] "A" ECU
  SG_ sig_7_1 : 7|1@0+ (1.0,0.0) [0.0|1.0] "" ECU
  SG_ sig_31_23 : 31|23@0- (1.000000000000001E-11,3.1622776601683795E-5) [-1.032026339831625E-5|7.356579660168383E-5] "km/h" ECU
  SG_ sig_23_8 : 23|8@0+ (1000.0,0.0) [0.0|254000.0] "km/h" ECU
  SG_ sig_40_1 : 40|1@1+ (1.0,0.0) [0.0|1.0] "" ECU

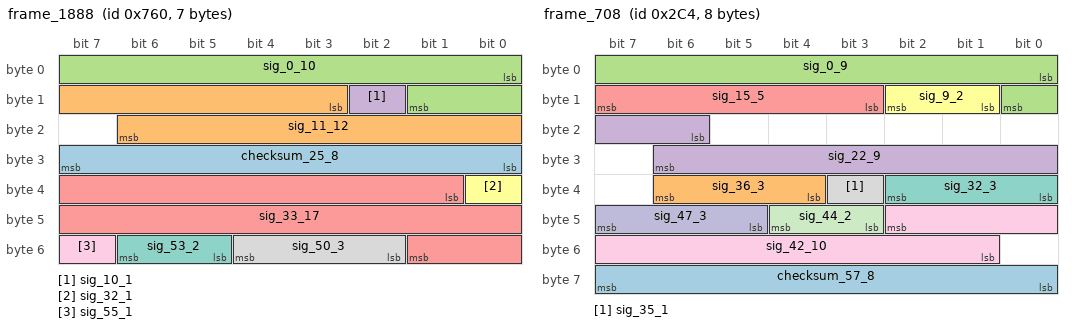
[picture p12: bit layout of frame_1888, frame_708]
BO_ 1888 frame_1888: 7 Vector__XXX
  SG_ checksum_25_8 : 24|8@1+ (1.0,0.0) [0.0|255.0] "" ECU
  SG_ sig_11_12 : 11|12@1- (0.0010000000000000002,3.1622776601683795) [1.114277660168379|5.20827766016838] "km/h" ECU
  SG_ sig_0_10 : 0|10@1+ (1.0000000000000006E-5,0.0031622776601683794) [0.0031622776601683794|0.013382277660168387] "V" ECU
  SG_ sig_10_1 : 10|1@1+ (1.0,0.0) [0.0|1.0] "" ECU
  SG_ sig_33_17 : 33|17@1- (0.010000000000000002,316.22776601683796) [-339.13223398316217|971.567766016838] "s" ECU
  SG_ sig_32_1 : 32|1@1+ (1.0,0.0) [0.0|1.0] "" ECU
  SG_ sig_53_2 : 53|2@1- (1.0,0.0) [-2.0|1.0] "" ECU
  SG_ sig_50_3 : 50|3@1+ (1.0,0.0) [0.0|6.0] "" ECU
  SG_ sig_55_1 : 55|1@1+ (1.0,0.0) [0.0|1.0] "" ECU

BO_ 981 frame_981: 6 ECU
  SG_ checksum_33_8 : 39|8@0+ (1.0,0.0) [0.0|255.0] "" Vector__XXX
  SG_ sig_9_10 : 9|10@0+ (10.0,0.0) [0.0|10220.0] "A" Vector__XXX
  SG_ sig_6_13 : 6|13@0- (1.0,0.0) [-4096.0|4094.0] "" Vector__XXX
  SG_ sig_7_1 : 7|1@0+ (1.0,0.0) [0.0|1.0] "" Vector__XXX
  SG_ sig_31_8 : 31|8@0- (1.0,0.0) [-128.0|126.0] "" Vector__XXX
  SG_ sig_47_8 : 47|8@0- (0.0010000000000000002,0.03162277660168379) [-0.09637722339831624|0.15762277660168383] "km/h" Vector__XXX

BO_ 708 frame_708: 8 ECU
  SG_ checksum_57_8 : 63|8@0+ (1.0,0.0) [0.0|255.0] "" Vector__XXX
  SG_ sig_36_3 : 36|3@1- (1.0,0.0) [-4.0|2.0] "" Vector__XXX
  SG_ sig_0_9 : 0|9@1+ (100.0,-31622.776601683792) [-31622.776601683792|19377.223398316208] "s" Vector__XXX
  SG_ sig_22_9 : 22|9@1+ (10.0,-3162.2776601683795) [-3162.2776601683795|1937.7223398316205] "W" Vector__XXX
  SG_ sig_15_5 : 15|5@0- (1.0,0.0) [-16.0|14.0] "" Vector__XXX
  SG_ sig_9_2 : 9|2@1- (1.0,0.0) [-2.0|1.0] "" Vector__XXX
  SG_ sig_32_3 : 32|3@1+ (1.0,0.0) [0.0|6.0] "" Vector__XXX
  SG_ sig_35_1 : 35|1@0+ (1.0,0.0) [0.0|1.0] "" Vector__XXX
  SG_ sig_42_10 : 42|10@0- (1.0000000000000008E-8,0.0) [-5.120000000000004E-6|5.1000000000000045E-6] "W" Vector__XXX
  SG_ sig_47_3 : 47|3@0- (1.0,0.0) [-4.0|2.0] "" Vector__XXX
  SG_ sig_44_2 : 44|2@0+ (1.0,0.0) [0.0|3.0] "" Vector__XXX

BO_ 1382 frame_1382: 4 Vector__XXX
  SG_ checksum_1_8 : 0|8@1+ (1.0,0.0) [0.0|255.0] "" ECU
  SG_ sig_17_15 : 17|15@1+ (1.0000000000000008E-8,3.1622776601683794E-4) [3.1622776601683794E-4|6.438877660168382E-4] "A" ECU
  SG_ sig_8_9 : 8|9@1- (1.0,0.0) [-256.0|254.0] "kWh" ECU

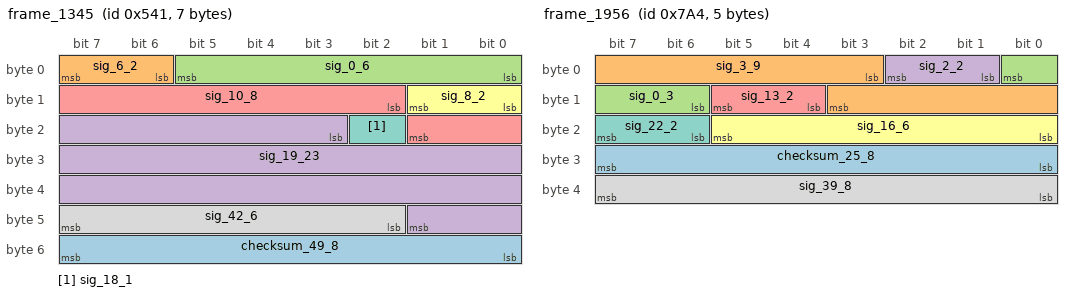
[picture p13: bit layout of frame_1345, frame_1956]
BO_ 1345 frame_1345: 7 Vector__XXX
  SG_ checksum_49_8 : 48|8@1+ (1.0,0.0) [0.0|255.0] "" ECU
  SG_ sig_6_2 : 6|2@1+ (1.0,0.0) [0.0|3.0] "" ECU
  SG_ sig_0_6 : 0|6@1- (1.0,0.0) [-32.0|30.0] "" ECU
  SG_ sig_19_23 : 19|23@1- (1.0000000000000007E-7,0.31622776601683794) [-0.10320263398316237|0.7356579660168383] "W" ECU
  SG_ sig_10_8 : 10|8@1+ (1.0,0.0) [0.0|254.0] "" ECU
  SG_ sig_8_2 : 8|2@1- (1.0,0.0) [-2.0|1.0] "" ECU
  SG_ sig_18_1 : 18|1@1+ (1.0,0.0) [0.0|1.0] "" ECU
  SG_ sig_42_6 : 42|6@1+ (1.0,0.0) [0.0|62.0] "" ECU

BO_ 1618 frame_1618: 4 ECU
  SG_ checksum_17_8 : 16|8@1+ (1.0,0.0) [0.0|255.0] "" Vector__XXX
  SG_ sig_3_12 : 3|12@1- (1.0,0.0) [-2048.0|2046.0] "" Vector__XXX
  SG_ sig_15_1 : 15|1@1+ (1.0,0.0) [0.0|1.0] "" Vector__XXX
  SG_ sig_25_6 : 25|6@1+ (1000.0,-31622.776601683792) [-31622.776601683792|30377.223398316208] "km/h" Vector__XXX
  SG_ sig_31_1 : 31|1@0+ (1.0,0.0) [0.0|1.0] "" Vector__XXX

BO_ 1956 frame_1956: 5 ECU
  SG_ checksum_25_8 : 24|8@1+ (1.0,0.0) [0.0|255.0] "" Vector__XXX
  SG_ sig_3_9 : 3|9@1- (1.0,0.0) [-256.0|254.0] "" Vector__XXX
  SG_ sig_0_3 : 0|3@0+ (1.0,0.0) [0.0|6.0] "" Vector__XXX
  SG_ sig_2_2 : 2|2@0- (1.0,0.0) [-2.0|1.0] "" Vector__XXX
  SG_ sig_13_2 : 13|2@0- (1.0,0.0) [-2.0|1.0] "" Vector__XXX
  SG_ sig_16_6 : 16|6@1- (0.010000000000000002,0.31622776601683794) [-0.003772233983162121|0.616227766016838] "kWh" Vector__XXX
  SG_ sig_22_2 : 22|2@1- (1.0,0.0) [-2.0|1.0] "" Vector__XXX
  SG_ sig_39_8 : 39|8@0- (1.0000000000000006E-5,3.1622776601683794E-4) [-9.637722339831628E-4|0.0015762277660168386] "A" Vector__XXX

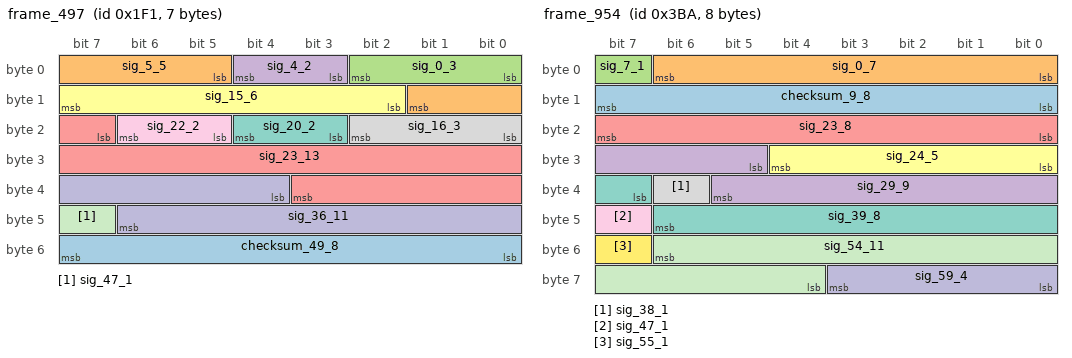
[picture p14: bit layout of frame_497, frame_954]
BO_ 497 frame_497: 7 Vector__XXX
  SG_ checksum_49_8 : 55|8@0+ (1.0,0.0) [0.0|255.0] "" ECU
  SG_ sig_5_5 : 5|5@1- (1.0000000000000007E-7,3.162277660168379E-6) [1.562277660168378E-6|4.56227766016838E-6] "kWh" ECU
  SG_ sig_0_3 : 0|3@1- (1.0,0.0) [-4.0|2.0] "" ECU
  SG_ sig_4_2 : 4|2@0- (1.0,0.0) [-2.0|1.0] "" ECU
  SG_ sig_23_13 : 23|13@1- (0.1,316.22776601683796) [-93.37223398316206|725.627766016838] "W" ECU
  SG_ sig_15_6 : 15|6@0+ (1.0,0.0) [0.0|62.0] "" ECU
  SG_ sig_20_2 : 20|2@0- (1.0,0.0) [-2.0|1.0] "" ECU
  SG_ sig_16_3 : 16|3@1+ (1.0,0.0) [0.0|6.0] "" ECU
  SG_ sig_22_2 : 22|2@0+ (1.0,0.0) [0.0|3.0] "" ECU
  SG_ sig_36_11 : 36|11@1- (1.0,0.0) [-1024.0|1022.0] "" ECU
  SG_ sig_47_1 : 47|1@1+ (1.0,0.0) [0.0|1.0] "" ECU

BO_ 463 frame_463: 4 ECU
  SG_ checksum_9_8 : 8|8@1+ (1.0,0.0) [0.0|255.0] "" Vector__XXX
  SG_ sig_3_5 : 3|5@1- (1.0,0.0) [-16.0|14.0] "" Vector__XXX
  SG_ sig_0_1 : 0|1@1+ (1.0,0.0) [0.0|1.0] "" Vector__XXX
  SG_ sig_23_13 : 23|13@0+ (0.0010000000000000002,0.0) [0.0|8.190000000000001] "A" Vector__XXX
  SG_ sig_25_2 : 25|2@1+ (1.0,0.0) [0.0|3.0] "" Vector__XXX

BO_ 954 frame_954: 8 ECU
  SG_ checksum_9_8 : 8|8@1+ (1.0,0.0) [0.0|255.0] "" Vector__XXX
  SG_ sig_0_7 : 0|7@1+ (1.0,0.0) [0.0|126.0] "" Vector__XXX
  SG_ sig_7_1 : 7|1@1+ (1.0,0.0) [0.0|1.0] "" Vector__XXX
  SG_ sig_29_9 : 29|9@1+ (1.0,0.0) [0.0|510.0] "" Vector__XXX
  SG_ sig_23_8 : 23|8@0+ (1.0,-31.622776601683793) [-31.622776601683793|222.3772233983162] "s" Vector__XXX
  SG_ sig_24_5 : 24|5@1- (1.0,0.0) [-16.0|14.0] "" Vector__XXX
  SG_ sig_39_8 : 39|8@1+ (10.0,316.22776601683796) [316.22776601683796|2856.227766016838] "s" Vector__XXX
  SG_ sig_38_1 : 38|1@1+ (1.0,0.0) [0.0|1.0] "" Vector__XXX
  SG_ sig_47_1 : 47|1@0+ (1.0,0.0) [0.0|1.0] "" Vector__XXX
  SG_ sig_59_4 : 59|4@0+ (1.0000000000000005E-4,3.1622776601683794E-4) [3.1622776601683794E-4|0.0017162277660168386] "V" Vector__XXX
  SG_ sig_54_11 : 54|11@0- (1.0,316.22776601683796) [-707.7722339831621|1338.227766016838] "m/s^2" Vector__XXX
  SG_ sig_55_1 : 55|1@1+ (1.0,0.0) [0.0|1.0] "" Vector__XXX

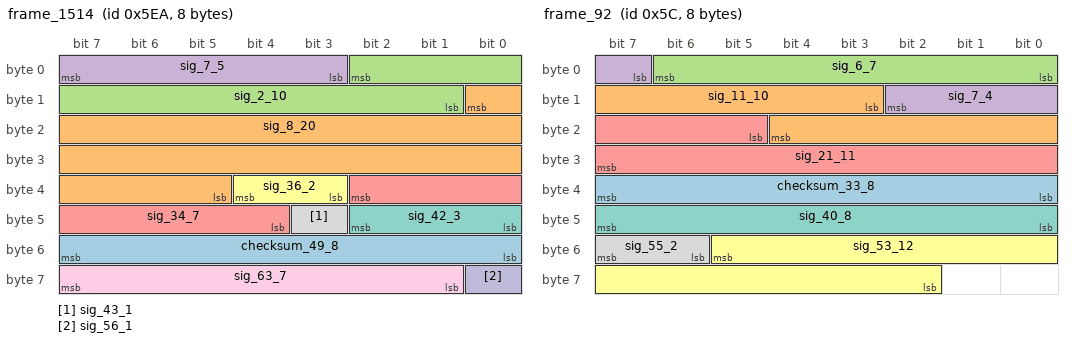
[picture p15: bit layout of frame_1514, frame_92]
BO_ 1514 frame_1514: 8 Vector__XXX
  SG_ checksum_49_8 : 55|8@0+ (1.0,0.0) [0.0|255.0] "" ECU
  SG_ sig_8_20 : 8|20@0- (1.0000000000000006E-6,0.31622776601683794) [-0.20806023398316237|0.8405137660168382] "kWh" ECU
  SG_ sig_2_10 : 2|10@0+ (0.1,0.0) [0.0|102.2] "s" ECU
  SG_ sig_7_5 : 7|5@0- (1.0000000000000006E-5,0.0) [-1.600000000000001E-4|1.400000000000001E-4] "m/s^2" ECU
  SG_ sig_34_7 : 34|7@0- (0.010000000000000002,-0.31622776601683794) [-0.9562277660168381|0.30377223398316217] "m/s^2" ECU
  SG_ sig_36_2 : 36|2@0- (1.0,0.0) [-2.0|1.0] "" ECU
  SG_ sig_42_3 : 42|3@0+ (1.0,0.0) [0.0|6.0] "" ECU
  SG_ sig_43_1 : 43|1@0+ (1.0,0.0) [0.0|1.0] "" ECU
  SG_ sig_63_7 : 63|7@0- (1.0,0.0) [-64.0|62.0] "" ECU
  SG_ sig_56_1 : 56|1@0+ (1.0,0.0) [0.0|1.0] "" ECU

BO_ 92 frame_92: 8 Vector__XXX
  SG_ checksum_33_8 : 32|8@1+ (1.0,0.0) [0.0|255.0] "" ECU
  SG_ sig_11_10 : 11|10@1+ (10.0,0.0) [0.0|10220.0] "W" ECU
  SG_ sig_6_7 : 6|7@0- (1.0,0.0) [-64.0|62.0] "" ECU
  SG_ sig_7_4 : 7|4@1+ (1.0,0.0) [0.0|14.0] "" ECU
  SG_ sig_21_11 : 21|11@1+ (10.0,-3162.2776601683795) [-3162.2776601683795|17297.72233983162] "s" ECU
  SG_ sig_53_12 : 53|12@0+ (1.0,0.0) [0.0|4094.0] "" ECU
  SG_ sig_40_8 : 40|8@1+ (10.0,0.0) [0.0|2540.0] "s" ECU
  SG_ sig_55_2 : 55|2@0+ (1.0,0.0) [0.0|3.0] "" ECU

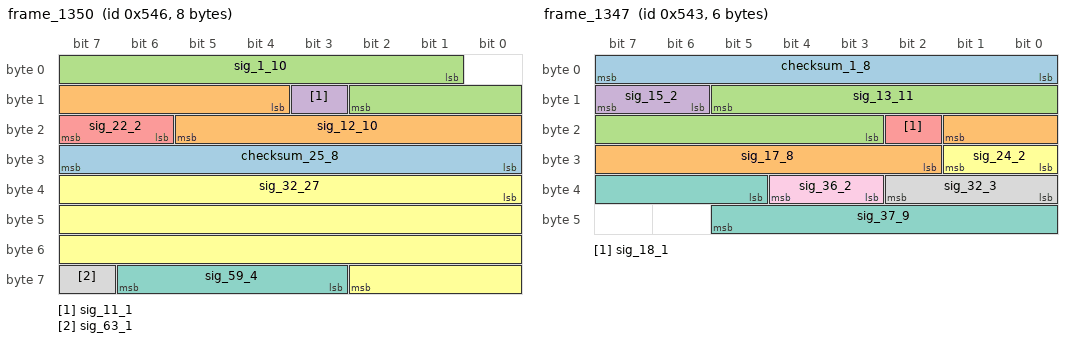
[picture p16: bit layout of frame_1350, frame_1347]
BO_ 1350 frame_1350: 8 Vector__XXX
  SG_ checksum_25_8 : 24|8@1+ (1.0,0.0) [0.0|255.0] "" ECU
  SG_ sig_12_10 : 12|10@1- (10.0,0.0) [-5120.0|5100.0] "s" ECU
  SG_ sig_1_10 : 1|10@1- (1.0000000000000006E-6,0.0) [-5.120000000000003E-4|5.100000000000003E-4] "W" ECU
  SG_ sig_11_1 : 11|1@1+ (1.0,0.0) [0.0|1.0] "" ECU
  SG_ sig_22_2 : 22|2@1+ (1.0,0.0) [0.0|3.0] "" ECU
  SG_ sig_32_27 : 32|27@1- (1.000000000000001E-11,-3.1622776601683794E-4) [-9.873164060168387E-4|3.5486085398316275E-4] "V" ECU
  SG_ sig_59_4 : 59|4@1+ (0.1,0.0) [0.0|1.4000000000000001] "s" ECU
  SG_ sig_63_1 : 63|1@1+ (1.0,0.0) [0.0|1.0] "" ECU

BO_ 1126 frame_1126: 7 ECU
  SG_ checksum_1_8 : 7|8@0+ (1.0,0.0) [0.0|255.0] "" Vector__XXX
  SG_ sig_14_18 : 14|18@0- (1.0000000000000007E-7,0.0) [-0.01310720000000001|0.01310700000000001] "m/s^2" Vector__XXX
  SG_ sig_15_1 : 15|1@0+ (1.0,0.0) [0.0|1.0] "" Vector__XXX
  SG_ sig_28_5 : 28|5@0- (1000.0,31622.776601683792) [15622.776601683792|45622.77660168379] "W" Vector__XXX
  SG_ sig_46_14 : 46|14@0- (1.0,0.0) [-8192.0|8190.0] "" Vector__XXX
  SG_ sig_48_1 : 48|1@0+ (1.0,0.0) [0.0|1.0] "" Vector__XXX

BO_ 1347 frame_1347: 6 Vector__XXX
  SG_ checksum_1_8 : 7|8@0+ (1.0,0.0) [0.0|255.0] "" ECU
  SG_ sig_17_8 : 17|8@0- (1.0,0.0) [-128.0|126.0] "" ECU
  SG_ sig_13_11 : 13|11@0+ (1.0,0.0) [0.0|2046.0] "" ECU
  SG_ sig_15_2 : 15|2@0+ (1.0,0.0) [0.0|3.0] "" ECU
  SG_ sig_18_1 : 18|1@0+ (1.0,0.0) [0.0|1.0] "" ECU
  SG_ sig_24_2 : 24|2@1+ (1.0,0.0) [0.0|3.0] "" ECU
  SG_ sig_37_9 : 37|9@1- (1.0000000000000006E-5,-0.0031622776601683794) [-0.005722277660168381|-6.222776601683779E-4] "s" ECU
  SG_ sig_32_3 : 32|3@1- (1.0,0.0) [-4.0|2.0] "" ECU
  SG_ sig_36_2 : 36|2@0+ (1.0,0.0) [0.0|3.0] "" ECU

BO_ 31 frame_31: 3 Vector__XXX
  SG_ checksum_1_8 : 7|8@0+ (1.0,0.0) [0.0|255.0] "" ECU
  SG_ sig_15_12 : 15|12@0- (1.0,0.0) [-2048.0|2046.0] "" ECU
  SG_ sig_19_4 : 19|4@0+ (1.0000000000000006E-5,3.1622776601683795E-5) [3.1622776601683795E-5|1.7162277660168388E-4] "km/h" ECU

BO_ 1694 frame_1694: 6 Vector__XXX
  SG_ checksum_9_8 : 15|8@0+ (1.0,0.0) [0.0|255.0] "" ECU
  SG_ sig_24_18 : 24|18@1- (0.0010000000000000002,-31.622776601683793) [-162.69477660168383|99.44722339831623] "km/h" ECU
  SG_ sig_22_7 : 22|7@0+ (0.0010000000000000002,0.0) [0.0|0.12600000000000003] "s" ECU
  SG_ sig_23_1 : 23|1@1+ (1.0,0.0) [0.0|1.0] "" ECU
  SG_ sig_45_4 : 45|4@0+ (1.0,0.0) [0.0|14.0] "" ECU
  SG_ sig_47_2 : 47|2@0- (1.0,0.0) [-2.0|1.0] "" ECU

BO_ 725 frame_725: 7 Vector__XXX
  SG_ checksum_25_8 : 31|8@0+ (1.0,0.0) [0.0|255.0] "" ECU
  SG_ sig_6_15 : 6|15@1+ (1.0000000000000007E-7,0.0031622776601683794) [0.0031622776601683794|0.006438877660168382] "V" ECU
  SG_ sig_1_2 : 1|2@0- (1.0,0.0) [-2.0|1.0] "" ECU
  SG_ sig_23_3 : 23|3@0- (1.0,0.0) [-4.0|2.0] "" ECU
  SG_ sig_35_14 : 35|14@0+ (1.0,0.0) [0.0|16382.0] "s" ECU
  SG_ sig_36_3 : 36|3@1+ (1.0,0.0) [0.0|6.0] "" ECU
  SG_ sig_53_6 : 53|6@0- (1000.0,-31622.776601683792) [-63622.77660168379|-1622.7766016837923] "A" ECU

BO_ 729 frame_729: 6 ECU
  SG_ checksum_25_8 : 24|8@1+ (1.0,0.0) [0.0|255.0] "" Vector__XXX
  SG_ sig_5_17 : 5|17@0+ (1.0,0.0) [0.0|131070.0] "" Vector__XXX
  SG_ sig_7_2 : 7|2@0+ (1.0,0.0) [0.0|3.0] "" Vector__XXX
  SG_ sig_17_4 : 17|4@1+ (10000.0,0.0) [0.0|140000.0] "W" Vector__XXX
  SG_ sig_35_12 : 35|12@1- (1.0000000000000009E-9,0.0) [-2.048000000000002E-6|2.0460000000000017E-6] "A" Vector__XXX
  SG_ sig_32_3 : 32|3@1+ (1.0,0.0) [0.0|6.0] "" Vector__XXX

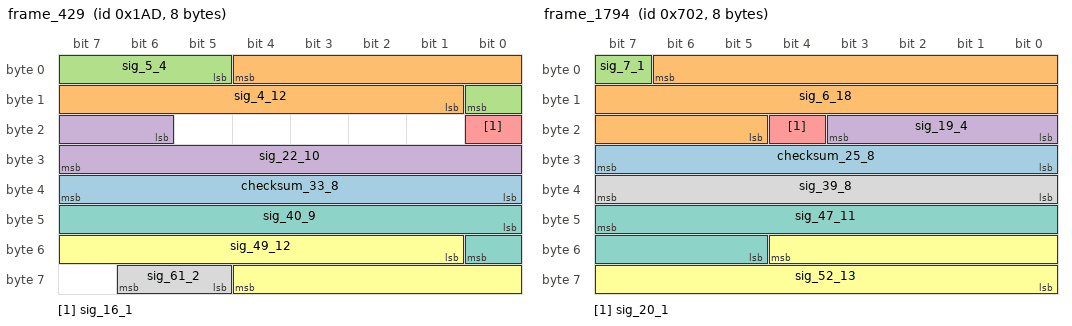
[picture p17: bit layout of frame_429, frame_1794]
BO_ 429 frame_429: 8 Vector__XXX
  SG_ checksum_33_8 : 39|8@0+ (1.0,0.0) [0.0|255.0] "" ECU
  SG_ sig_4_12 : 4|12@0+ (1.0,-3162.2776601683795) [-3162.2776601683795|931.7223398316205] "kWh" ECU
  SG_ sig_5_4 : 5|4@1- (1.0,0.0) [-8.0|6.0] "" ECU
  SG_ sig_22_10 : 22|10@1- (1.0,0.0) [-512.0|510.0] "" ECU
  SG_ sig_16_1 : 16|1@1+ (1.0,0.0) [0.0|1.0] "" ECU
  SG_ sig_49_12 : 49|12@1- (1.0,0.0) [-2048.0|2046.0] "" ECU
  SG_ sig_40_9 : 40|9@1- (1.0,0.0) [-256.0|254.0] "" ECU
  SG_ sig_61_2 : 61|2@1- (1.0,0.0) [-2.0|1.0] "" ECU

BO_ 633 frame_633: 2 Vector__XXX
  SG_ checksum_9_8 : 8|8@1+ (1.0,0.0) [0.0|255.0] "" ECU
  SG_ sig_0_8 : 0|8@1+ (1.0,0.0) [0.0|254.0] "" ECU

BO_ 2045 frame_2045: 5 ECU
  SG_ checksum_9_8 : 8|8@1+ (1.0,0.0) [0.0|255.0] "" Vector__XXX
  SG_ sig_0_8 : 0|8@1- (10.0,0.0) [-1280.0|1260.0] "m/s^2" Vector__XXX
  SG_ sig_21_16 : 21|16@0+ (0.010000000000000002,-316.22776601683796) [-316.22776601683796|339.1122339831622] "kWh" Vector__XXX
  SG_ sig_23_2 : 23|2@0+ (1.0,0.0) [0.0|3.0] "" Vector__XXX
  SG_ sig_37_6 : 37|6@0+ (1.0,0.0) [0.0|62.0] "" Vector__XXX

BO_ 1005 frame_1005: 6 Vector__XXX
  SG_ checksum_1_8 : 7|8@0+ (1.0,0.0) [0.0|255.0] "" ECU
  SG_ sig_19_16 : 19|16@0+ (1.0000000000000005E-4,-3.1622776601683795) [-3.1622776601683795|3.391122339831623] "A" ECU
  SG_ sig_8_8 : 8|8@1+ (1.0000000000000007E-7,0.0) [0.0|2.5400000000000018E-5] "kWh" ECU
  SG_ sig_20_3 : 20|3@1+ (1.0,0.0) [0.0|6.0] "" ECU
  SG_ sig_23_1 : 23|1@0+ (1.0,0.0) [0.0|1.0] "" ECU
  SG_ sig_32_4 : 32|4@1- (1.0,0.0) [-8.0|6.0] "" ECU
  SG_ sig_40_8 : 40|8@1- (1.0,0.0) [-128.0|126.0] "" ECU

BO_ 1794 frame_1794: 8 Vector__XXX
  SG_ checksum_25_8 : 31|8@0+ (1.0,0.0) [0.0|255.0] "" ECU
  SG_ sig_6_18 : 6|18@0+ (1.0000000000000007E-7,0.0031622776601683794) [0.0031622776601683794|0.0293764776601684] "m/s^2" ECU
  SG_ sig_7_1 : 7|1@0+ (1.0,0.0) [0.0|1.0] "" ECU
  SG_ sig_19_4 : 19|4@0- (1000.0,3162.2776601683795) [-4837.72233983162|9162.27766016838] "A" ECU
  SG_ sig_20_1 : 20|1@0+ (1.0,0.0) [0.0|1.0] "" ECU
  SG_ sig_52_13 : 52|13@0- (1.0,0.0) [-4096.0|4094.0] "" ECU
  SG_ sig_47_11 : 47|11@0+ (1.0,0.0) [0.0|2046.0] "" ECU
  SG_ sig_39_8 : 39|8@0- (1.0,0.0) [-128.0|126.0] "" ECU

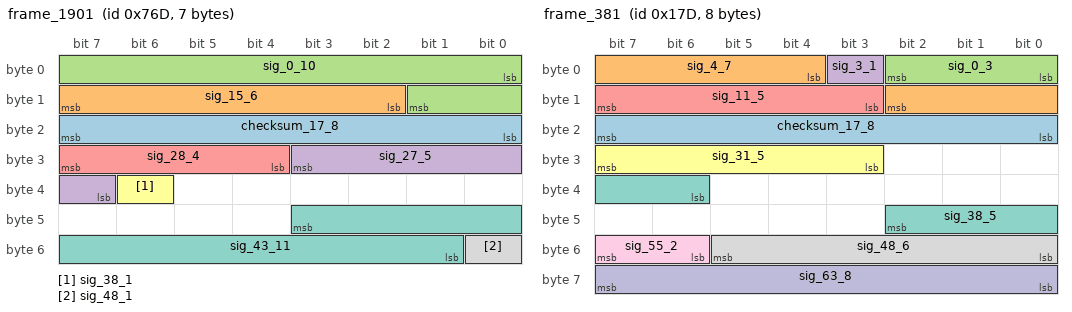
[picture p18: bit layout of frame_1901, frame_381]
BO_ 1901 frame_1901: 7 ECU
  SG_ checksum_17_8 : 16|8@1+ (1.0,0.0) [0.0|255.0] "" Vector__XXX
  SG_ sig_15_6 : 15|6@0+ (1.0,0.0) [0.0|62.0] "" Vector__XXX
  SG_ sig_0_10 : 0|10@1+ (10.0,0.0) [0.0|10220.0] "V" Vector__XXX
  SG_ sig_27_5 : 27|5@0+ (1.0,0.0) [0.0|30.0] "" Vector__XXX
  SG_ sig_28_4 : 28|4@1- (1.0000000000000006E-5,-3.1622776601683795E-5) [-1.1162277660168384E-4|2.837722339831624E-5] "m/s^2" Vector__XXX
  SG_ sig_38_1 : 38|1@1+ (1.0,0.0) [0.0|1.0] "" Vector__XXX
  SG_ sig_43_11 : 43|11@0- (10.0,0.0) [-10240.0|10220.0] "V" Vector__XXX
  SG_ sig_48_1 : 48|1@1+ (1.0,0.0) [0.0|1.0] "" Vector__XXX

BO_ 1010 frame_1010: 5 Vector__XXX
  SG_ checksum_33_8 : 32|8@1+ (1.0,0.0) [0.0|255.0] "" ECU
  SG_ sig_6_19 : 6|19@0+ (0.010000000000000002,-3162.2776601683795) [-3162.2776601683795|2080.582339831621] "A" ECU
  SG_ sig_7_1 : 7|1@1+ (1.0,0.0) [0.0|1.0] "" ECU
  SG_ sig_24_8 : 24|8@1+ (0.1,-3.1622776601683795) [-3.1622776601683795|22.237722339831624] "V" ECU

BO_ 381 frame_381: 8 ECU
  SG_ checksum_17_8 : 23|8@0+ (1.0,0.0) [0.0|255.0] "" Vector__XXX
  SG_ sig_4_7 : 4|7@1- (100.0,0.0) [-6400.0|6200.0] "A" Vector__XXX
  SG_ sig_0_3 : 0|3@1+ (1.0,0.0) [0.0|6.0] "" Vector__XXX
  SG_ sig_3_1 : 3|1@1+ (1.0,0.0) [0.0|1.0] "" Vector__XXX
  SG_ sig_11_5 : 11|5@1+ (1.0,0.0) [0.0|30.0] "" Vector__XXX
  SG_ sig_31_5 : 31|5@0- (0.1,3.1622776601683795) [1.5622776601683794|4.562277660168379] "V" Vector__XXX
  SG_ sig_38_5 : 38|5@1+ (1.0,0.0) [0.0|30.0] "" Vector__XXX
  SG_ sig_48_6 : 48|6@1- (1.0000000000000007E-7,0.0) [-3.2000000000000024E-6|3.000000000000002E-6] "kWh" Vector__XXX
  SG_ sig_55_2 : 55|2@0- (1.0,0.0) [-2.0|1.0] "" Vector__XXX
  SG_ sig_63_8 : 63|8@0- (1.0000000000000007E-7,-3.162277660168379E-6) [-1.596227766016839E-5|9.43772233983163E-6] "s" Vector__XXX

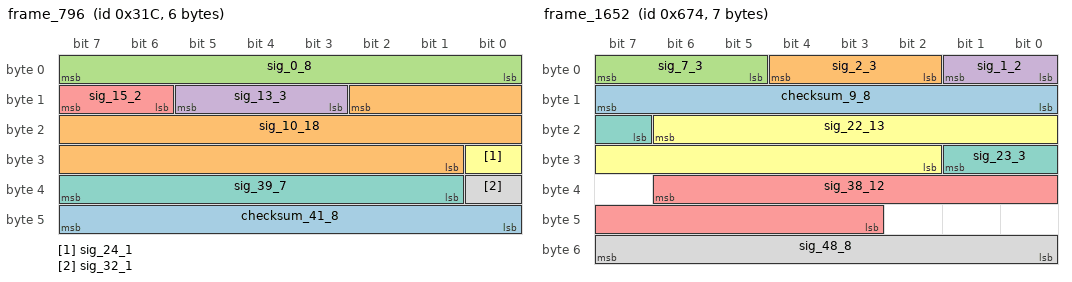
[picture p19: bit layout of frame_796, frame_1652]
BO_ 796 frame_796: 6 ECU
  SG_ checksum_41_8 : 40|8@1+ (1.0,0.0) [0.0|255.0] "" Vector__XXX
  SG_ sig_10_18 : 10|18@0+ (1.0000000000000006E-5,0.31622776601683794) [0.31622776601683794|2.9376477660168394] "V" Vector__XXX
  SG_ sig_0_8 : 0|8@1- (1.0000000000000007E-7,0.0) [-1.280000000000001E-5|1.260000000000001E-5] "V" Vector__XXX
  SG_ sig_13_3 : 13|3@0+ (1.0,0.0) [0.0|6.0] "" Vector__XXX
  SG_ sig_15_2 : 15|2@0+ (1.0,0.0) [0.0|3.0] "" Vector__XXX
  SG_ sig_24_1 : 24|1@1+ (1.0,0.0) [0.0|1.0] "" Vector__XXX
  SG_ sig_39_7 : 39|7@0- (1.0,0.0) [-64.0|62.0] "" Vector__XXX
  SG_ sig_32_1 : 32|1@0+ (1.0,0.0) [0.0|1.0] "" Vector__XXX

BO_ 260 frame_260: 7 Vector__XXX
  SG_ checksum_41_8 : 40|8@1+ (1.0,0.0) [0.0|255.0] "" ECU
  SG_ sig_3_14 : 3|14@1- (1.0,0.0) [-8192.0|8190.0] "" ECU
  SG_ sig_2_3 : 2|3@0+ (1.0,0.0) [0.0|6.0] "" ECU
  SG_ sig_21_8 : 21|8@1- (1.0,0.0) [-128.0|126.0] "" ECU
  SG_ sig_17_4 : 17|4@1- (1.0,3.1622776601683795) [-4.83772233983162|9.16227766016838] "kWh" ECU
  SG_ sig_29_11 : 29|11@1- (1.0000000000000006E-6,3.1622776601683794E-4) [-7.077722339831627E-4|0.0013382277660168385] "km/h" ECU
  SG_ sig_49_7 : 49|7@1+ (1.0,0.0) [0.0|126.0] "" ECU

BO_ 1337 frame_1337: 8 Vector__XXX
  SG_ checksum_57_8 : 63|8@0+ (1.0,0.0) [0.0|255.0] "" ECU
  SG_ sig_2_16 : 2|16@0+ (1.0000000000000011E-10,0.0) [0.0|6.553400000000007E-6] "s" ECU
  SG_ sig_17_15 : 17|15@0- (1.0,0.0) [-16384.0|16382.0] "" ECU
  SG_ sig_18_1 : 18|1@0+ (1.0,0.0) [0.0|1.0] "" ECU
  SG_ sig_43_8 : 43|8@0+ (1.0000000000000006E-5,0.0) [0.0|0.0025400000000000015] "W" ECU
  SG_ sig_34_7 : 34|7@0- (1.0000000000000006E-5,3.1622776601683794E-4) [-3.2377223398316244E-4|9.362277660168383E-4] "A" ECU
  SG_ sig_51_4 : 51|4@0+ (1.0,0.0) [0.0|14.0] "" ECU

BO_ 1652 frame_1652: 7 ECU
  SG_ checksum_9_8 : 15|8@0+ (1.0,0.0) [0.0|255.0] "" Vector__XXX
  SG_ sig_2_3 : 2|3@1- (1.0,0.0) [-4.0|2.0] "" Vector__XXX
  SG_ sig_7_3 : 7|3@0- (1.0,0.0) [-4.0|2.0] "" Vector__XXX
  SG_ sig_1_2 : 1|2@0+ (1.0,0.0) [0.0|3.0] "" Vector__XXX
  SG_ sig_38_12 : 38|12@0+ (1.0,0.0) [0.0|4094.0] "" Vector__XXX
  SG_ sig_22_13 : 22|13@0+ (1.0000000000000006E-5,0.03162277660168379) [0.03162277660168379|0.11352277660168383] "km/h" Vector__XXX
  SG_ sig_23_3 : 23|3@1+ (1.0,0.0) [0.0|6.0] "" Vector__XXX
  SG_ sig_48_8 : 48|8@1- (1.0,0.0) [-128.0|126.0] "" Vector__XXX

BO_ 1442 frame_1442: 2 ECU
  SG_ checksum_1_8 : 7|8@0+ (1.0,0.0) [0.0|255.0] "" Vector__XXX
  SG_ sig_14_5 : 14|5@0- (1.0000000000000006E-6,-3.1622776601683795E-5) [-4.7622776601683805E-5|-1.7622776601683787E-5] "W" Vector__XXX
  SG_ sig_15_1 : 15|1@0+ (1.0,0.0) [0.0|1.0] "" Vector__XXX
  SG_ sig_9_2 : 9|2@0- (1.0,0.0) [-2.0|1.0] "" Vector__XXX

CM_ BO_ 90 "Randomly defined CAN frame";
CM_ SG_ 90 checksum_1_8 "8 Bit checksum for protection of frame contents";
CM_ BO_ 1675 "Randomly defined CAN frame";
CM_ SG_ 1675 checksum_9_8 "8 Bit checksum for protection of frame contents";
CM_ BO_ 261 "Randomly defined CAN frame";
CM_ SG_ 261 checksum_33_8 "8 Bit checksum for protection of frame contents";
CM_ BO_ 660 "Randomly defined CAN frame";
CM_ SG_ 660 checksum_9_8 "8 Bit checksum for protection of frame contents";
CM_ BO_ 1074 "Randomly defined CAN frame";
CM_ SG_ 1074 checksum_25_8 "8 Bit checksum for protection of frame contents";
CM_ BO_ 25 "Randomly defined CAN frame";
CM_ SG_ 25 checksum_1_8 "8 Bit checksum for protection of frame contents";
CM_ BO_ 1747 "Randomly defined CAN frame";
CM_ SG_ 1747 checksum_17_8 "8 Bit checksum for protection of frame contents";
CM_ BO_ 1641 "Randomly defined CAN frame";
CM_ SG_ 1641 checksum_25_8 "8 Bit checksum for protection of frame contents";
CM_ BO_ 786 "Randomly defined CAN frame";
CM_ SG_ 786 checksum_1_8 "8 Bit checksum for protection of frame contents";
CM_ BO_ 341 "Randomly defined CAN frame";
CM_ SG_ 341 checksum_25_8 "8 Bit checksum for protection of frame contents";
CM_ BO_ 1400 "Randomly defined CAN frame";
CM_ SG_ 1400 checksum_17_8 "8 Bit checksum for protection of frame contents";
CM_ BO_ 1545 "Randomly defined CAN frame";
CM_ SG_ 1545 checksum_17_8 "8 Bit checksum for protection of frame contents";
CM_ BO_ 669 "Randomly defined CAN frame";
CM_ SG_ 669 checksum_25_8 "8 Bit checksum for protection of frame contents";
CM_ BO_ 328 "Randomly defined CAN frame";
CM_ SG_ 328 checksum_25_8 "8 Bit checksum for protection of frame contents";
CM_ BO_ 844 "Randomly defined CAN frame";
CM_ SG_ 844 checksum_33_8 "8 Bit checksum for protection of frame contents";
CM_ BO_ 196 "Randomly defined CAN frame";
CM_ SG_ 196 checksum_9_8 "8 Bit checksum for protection of frame contents";
CM_ BO_ 870 "Randomly defined CAN frame";
CM_ SG_ 870 checksum_9_8 "8 Bit checksum for protection of frame contents";
CM_ BO_ 1492 "Randomly defined CAN frame";
CM_ SG_ 1492 checksum_9_8 "8 Bit checksum for protection of frame contents";
CM_ BO_ 1401 "Randomly defined CAN frame";
CM_ SG_ 1401 checksum_25_8 "8 Bit checksum for protection of frame contents";
CM_ BO_ 1413 "Randomly defined CAN frame";
CM_ SG_ 1413 checksum_33_8 "8 Bit checksum for protection of frame contents";
CM_ BO_ 1185 "Randomly defined CAN frame";
CM_ SG_ 1185 checksum_33_8 "8 Bit checksum for protection of frame contents";
CM_ BO_ 322 "Randomly defined CAN frame";
CM_ SG_ 322 checksum_41_8 "8 Bit checksum for protection of frame contents";
CM_ BO_ 1188 "Randomly defined CAN frame";
CM_ SG_ 1188 checksum_41_8 "8 Bit checksum for protection of frame contents";
CM_ BO_ 1340 "Randomly defined CAN frame";
CM_ SG_ 1340 checksum_9_8 "8 Bit checksum for protection of frame contents";
CM_ BO_ 1151 "Randomly defined CAN frame";
CM_ SG_ 1151 checksum_9_8 "8 Bit checksum for protection of frame contents";
CM_ BO_ 2012 "Randomly defined CAN frame";
CM_ SG_ 2012 checksum_9_8 "8 Bit checksum for protection of frame contents";
CM_ BO_ 1041 "Randomly defined CAN frame";
CM_ SG_ 1041 checksum_1_8 "8 Bit checksum for protection of frame contents";
CM_ BO_ 287 "Randomly defined CAN frame";
CM_ SG_ 287 checksum_25_8 "8 Bit checksum for protection of frame contents";
CM_ BO_ 138 "Randomly defined CAN frame";
CM_ SG_ 138 checksum_1_8 "8 Bit checksum for protection of frame contents";
CM_ BO_ 1730 "Randomly defined CAN frame";
CM_ SG_ 1730 checksum_1_8 "8 Bit checksum for protection of frame contents";
CM_ BO_ 937 "Randomly defined CAN frame";
CM_ SG_ 937 checksum_1_8 "8 Bit checksum for protection of frame contents";
CM_ BO_ 490 "Randomly defined CAN frame";
CM_ SG_ 490 checksum_1_8 "8 Bit checksum for protection of frame contents";
CM_ BO_ 1827 "Randomly defined CAN frame";
CM_ SG_ 1827 checksum_33_8 "8 Bit checksum for protection of frame contents";
CM_ BO_ 1819 "Randomly defined CAN frame";
CM_ SG_ 1819 checksum_33_8 "8 Bit checksum for protection of frame contents";
CM_ BO_ 46 "Randomly defined CAN frame";
CM_ SG_ 46 checksum_17_8 "8 Bit checksum for protection of frame contents";
CM_ BO_ 1255 "Randomly defined CAN frame";
CM_ SG_ 1255 checksum_41_8 "8 Bit checksum for protection of frame contents";
CM_ BO_ 1036 "Randomly defined CAN frame";
CM_ SG_ 1036 checksum_1_8 "8 Bit checksum for protection of frame contents";
CM_ BO_ 1939 "Randomly defined CAN frame";
CM_ SG_ 1939 checksum_1_8 "8 Bit checksum for protection of frame contents";
CM_ BO_ 922 "Randomly defined CAN frame";
CM_ SG_ 922 checksum_41_8 "8 Bit checksum for protection of frame contents";
CM_ BO_ 759 "Randomly defined CAN frame";
CM_ SG_ 759 checksum_49_8 "8 Bit checksum for protection of frame contents";
CM_ BO_ 88 "Randomly defined CAN frame";
CM_ SG_ 88 checksum_1_8 "8 Bit checksum for protection of frame contents";
CM_ BO_ 162 "Randomly defined CAN frame";
CM_ SG_ 162 checksum_17_8 "8 Bit checksum for protection of frame contents";
CM_ BO_ 659 "Randomly defined CAN frame";
CM_ SG_ 659 checksum_41_8 "8 Bit checksum for protection of frame contents";
CM_ BO_ 495 "Randomly defined CAN frame";
CM_ SG_ 495 checksum_17_8 "8 Bit checksum for protection of frame contents";
CM_ BO_ 563 "Randomly defined CAN frame";
CM_ SG_ 563 checksum_9_8 "8 Bit checksum for protection of frame contents";
CM_ BO_ 1888 "Randomly defined CAN frame";
CM_ SG_ 1888 checksum_25_8 "8 Bit checksum for protection of frame contents";
CM_ BO_ 981 "Randomly defined CAN frame";
CM_ SG_ 981 checksum_33_8 "8 Bit checksum for protection of frame contents";
CM_ BO_ 708 "Randomly defined CAN frame";
CM_ SG_ 708 checksum_57_8 "8 Bit checksum for protection of frame contents";
CM_ BO_ 1382 "Randomly defined CAN frame";
CM_ SG_ 1382 checksum_1_8 "8 Bit checksum for protection of frame contents";
CM_ BO_ 1345 "Randomly defined CAN frame";
CM_ SG_ 1345 checksum_49_8 "8 Bit checksum for protection of frame contents";
CM_ BO_ 1618 "Randomly defined CAN frame";
CM_ SG_ 1618 checksum_17_8 "8 Bit checksum for protection of frame contents";
CM_ BO_ 1956 "Randomly defined CAN frame";
CM_ SG_ 1956 checksum_25_8 "8 Bit checksum for protection of frame contents";
CM_ BO_ 497 "Randomly defined CAN frame";
CM_ SG_ 497 checksum_49_8 "8 Bit checksum for protection of frame contents";
CM_ BO_ 463 "Randomly defined CAN frame";
CM_ SG_ 463 checksum_9_8 "8 Bit checksum for protection of frame contents";
CM_ BO_ 954 "Randomly defined CAN frame";
CM_ SG_ 954 checksum_9_8 "8 Bit checksum for protection of frame contents";
CM_ BO_ 1514 "Randomly defined CAN frame";
CM_ SG_ 1514 checksum_49_8 "8 Bit checksum for protection of frame contents";
CM_ BO_ 92 "Randomly defined CAN frame";
CM_ SG_ 92 checksum_33_8 "8 Bit checksum for protection of frame contents";
CM_ BO_ 1350 "Randomly defined CAN frame";
CM_ SG_ 1350 checksum_25_8 "8 Bit checksum for protection of frame contents";
CM_ BO_ 1126 "Randomly defined CAN frame";
CM_ SG_ 1126 checksum_1_8 "8 Bit checksum for protection of frame contents";
CM_ BO_ 1347 "Randomly defined CAN frame";
CM_ SG_ 1347 checksum_1_8 "8 Bit checksum for protection of frame contents";
CM_ BO_ 31 "Randomly defined CAN frame";
CM_ SG_ 31 checksum_1_8 "8 Bit checksum for protection of frame contents";
CM_ BO_ 1694 "Randomly defined CAN frame";
CM_ SG_ 1694 checksum_9_8 "8 Bit checksum for protection of frame contents";
CM_ BO_ 725 "Randomly defined CAN frame";
CM_ SG_ 725 checksum_25_8 "8 Bit checksum for protection of frame contents";
CM_ BO_ 729 "Randomly defined CAN frame";
CM_ SG_ 729 checksum_25_8 "8 Bit checksum for protection of frame contents";
CM_ BO_ 429 "Randomly defined CAN frame";
CM_ SG_ 429 checksum_33_8 "8 Bit checksum for protection of frame contents";
CM_ BO_ 633 "Randomly defined CAN frame";
CM_ SG_ 633 checksum_9_8 "8 Bit checksum for protection of frame contents";
CM_ BO_ 2045 "Randomly defined CAN frame";
CM_ SG_ 2045 checksum_9_8 "8 Bit checksum for protection of frame contents";
CM_ BO_ 1005 "Randomly defined CAN frame";
CM_ SG_ 1005 checksum_1_8 "8 Bit checksum for protection of frame contents";
CM_ BO_ 1794 "Randomly defined CAN frame";
CM_ SG_ 1794 checksum_25_8 "8 Bit checksum for protection of frame contents";
CM_ BO_ 1901 "Randomly defined CAN frame";
CM_ SG_ 1901 checksum_17_8 "8 Bit checksum for protection of frame contents";
CM_ BO_ 1010 "Randomly defined CAN frame";
CM_ SG_ 1010 checksum_33_8 "8 Bit checksum for protection of frame contents";
CM_ BO_ 381 "Randomly defined CAN frame";
CM_ SG_ 381 checksum_17_8 "8 Bit checksum for protection of frame contents";
CM_ BO_ 796 "Randomly defined CAN frame";
CM_ SG_ 796 checksum_41_8 "8 Bit checksum for protection of frame contents";
CM_ BO_ 260 "Randomly defined CAN frame";
CM_ SG_ 260 checksum_41_8 "8 Bit checksum for protection of frame contents";
CM_ BO_ 1337 "Randomly defined CAN frame";
CM_ SG_ 1337 checksum_57_8 "8 Bit checksum for protection of frame contents";
CM_ BO_ 1652 "Randomly defined CAN frame";
CM_ SG_ 1652 checksum_9_8 "8 Bit checksum for protection of frame contents";
CM_ BO_ 1442 "Randomly defined CAN frame";
CM_ SG_ 1442 checksum_1_8 "8 Bit checksum for protection of frame contents";
BA_DEF_ "Author" STRING;
BA_DEF_ BO_ "frameSendMode" ENUM  "regular","event","mixed";
BA_DEF_ BO_ "sendPeriod" INT 5 10000;
BA_DEF_ BO_ "crcStartValue" INT 1 255;
BA_DEF_ BO_ "eventMinDistance" INT 5 10000;
BA_DEF_ SG_ "initialValue" FLOAT -1e38 1e38;
BA_DEF_DEF_ "Author" "http://sourceforge.net/projects/comframe/";
BA_DEF_DEF_ "frameSendMode" "regular";
BA_DEF_DEF_ "sendPeriod" 10;
BA_DEF_DEF_ "crcStartValue" 1;
BA_DEF_DEF_ "eventMinDistance" 10;
BA_DEF_DEF_ "initialValue" 0.0;
BA_ "sendPeriod" BO_ 90 500;
BA_ "crcStartValue" BO_ 90 70;
BA_ "initialValue" SG_ 90 sig_16_36 2690.445319431625;
BA_ "initialValue" SG_ 90 sig_15_7 2362.2776601683795;
BA_ "initialValue" SG_ 90 sig_8_1 1.0;
BA_ "initialValue" SG_ 90 sig_52_10 0.09290000000000004;
BA_ "frameSendMode" BO_ 1675 2;
BA_ "sendPeriod" BO_ 1675 10000;
BA_ "eventMinDistance" BO_ 1675 500;
BA_ "crcStartValue" BO_ 1675 8;
BA_ "initialValue" SG_ 1675 sig_1_7 1.3962277660168383;
BA_ "initialValue" SG_ 1675 sig_21_11 55477.22339831621;
BA_ "initialValue" SG_ 1675 sig_26_9 0.009122776601683782;
BA_ "initialValue" SG_ 1675 sig_32_2 2.0;
BA_ "sendPeriod" BO_ 261 5;
BA_ "crcStartValue" BO_ 261 255;
BA_ "initialValue" SG_ 261 sig_15_3 4.0;
BA_ "initialValue" SG_ 261 sig_7_7 39.0;
BA_ "initialValue" SG_ 261 sig_0_1 1.0;
BA_ "initialValue" SG_ 261 sig_19_10 0.012212277660168386;
BA_ "initialValue" SG_ 261 sig_12_3 1.0;
BA_ "initialValue" SG_ 261 sig_47_8 0.02520000000000001;
BA_ "crcStartValue" BO_ 660 91;
BA_ "initialValue" SG_ 660 sig_0_8 4.56227766016838E-6;
BA_ "initialValue" SG_ 660 sig_17_14 0.011780000000000007;
BA_ "initialValue" SG_ 660 sig_31_1 1.0;
BA_ "sendPeriod" BO_ 1074 1000;
BA_ "crcStartValue" BO_ 1074 106;
BA_ "initialValue" SG_ 1074 sig_7_22 2.7557130000000014;
BA_ "initialValue" SG_ 1074 sig_37_14 70.01722339831622;
BA_ "initialValue" SG_ 1074 sig_39_2 3.0;
BA_ "sendPeriod" BO_ 25 100;
BA_ "crcStartValue" BO_ 25 187;
BA_ "initialValue" SG_ 25 sig_21_9 169.0;
BA_ "initialValue" SG_ 25 sig_15_10 143.77223398316204;
BA_ "initialValue" SG_ 25 sig_39_5 -14.0;
BA_ "initialValue" SG_ 25 sig_27_4 -483.77223398316204;
BA_ "initialValue" SG_ 25 sig_34_3 5.0;
BA_ "sendPeriod" BO_ 1747 50;
BA_ "crcStartValue" BO_ 1747 224;
BA_ "initialValue" SG_ 1747 sig_5_14 9998.0;
BA_ "initialValue" SG_ 1747 sig_6_2 3.0;
BA_ "initialValue" SG_ 1747 sig_26_28 103.98963260168384;
BA_ "initialValue" SG_ 1747 sig_31_5 18.0;
BA_ "initialValue" SG_ 1747 sig_62_7 4377.223398316208;
BA_ "frameSendMode" BO_ 1641 2;
BA_ "sendPeriod" BO_ 1641 1000;
BA_ "eventMinDistance" BO_ 1641 500;
BA_ "crcStartValue" BO_ 1641 239;
BA_ "initialValue" SG_ 1641 sig_5_15 0.0029558000000000023;
BA_ "initialValue" SG_ 1641 sig_4_5 0.002200000000000001;
BA_ "initialValue" SG_ 1641 sig_32_8 0.005262277660168381;
BA_ "crcStartValue" BO_ 786 131;
BA_ "initialValue" SG_ 786 sig_20_9 0.0037622776601683797;
BA_ "initialValue" SG_ 786 sig_15_8 81.0;
BA_ "initialValue" SG_ 786 sig_27_4 0.00816227766016838;
BA_ "crcStartValue" BO_ 341 170;
BA_ "initialValue" SG_ 341 sig_2_12 -2.1932776601683784E-6;
BA_ "initialValue" SG_ 341 sig_1_1 1.0;
BA_ "initialValue" SG_ 341 sig_14_1 1.0;
BA_ "initialValue" SG_ 341 sig_23_6 -3.0000000000000014E-4;
BA_ "initialValue" SG_ 341 sig_39_14 -0.428527766016838;
BA_ "initialValue" SG_ 341 sig_40_7 35.0;
BA_ "sendPeriod" BO_ 1400 10000;
BA_ "crcStartValue" BO_ 1400 194;
BA_ "initialValue" SG_ 1400 sig_4_13 1180.0;
BA_ "initialValue" SG_ 1400 sig_5_3 -3.0;
BA_ "initialValue" SG_ 1400 sig_38_7 3.1622776601683794E-4;
BA_ "initialValue" SG_ 1400 sig_31_7 2.0;
BA_ "initialValue" SG_ 1400 sig_24_1 1.0;
BA_ "initialValue" SG_ 1400 sig_36_8 140.0;
BA_ "initialValue" SG_ 1400 sig_50_10 0.05037722339831624;
BA_ "initialValue" SG_ 1400 sig_51_5 900.0;
BA_ "sendPeriod" BO_ 1545 10000;
BA_ "crcStartValue" BO_ 1545 16;
BA_ "initialValue" SG_ 1545 sig_5_4 20000.0;
BA_ "initialValue" SG_ 1545 sig_4_7 87.0;
BA_ "initialValue" SG_ 1545 sig_13_5 -2.3622776601683784E-6;
BA_ "initialValue" SG_ 1545 sig_25_7 9.200000000000006E-4;
BA_ "initialValue" SG_ 1545 sig_27_8 0.01483772233983163;
BA_ "initialValue" SG_ 1545 sig_45_8 -54.0;
BA_ "initialValue" SG_ 1545 sig_40_5 0.030000000000000006;
BA_ "initialValue" SG_ 1545 sig_53_3 5.0;
BA_ "sendPeriod" BO_ 669 1000;
BA_ "crcStartValue" BO_ 669 99;
BA_ "initialValue" SG_ 669 sig_7_17 9031.07766016838;
BA_ "initialValue" SG_ 669 sig_16_6 0.002737722339831623;
BA_ "initialValue" SG_ 669 sig_22_1 1.0;
BA_ "initialValue" SG_ 669 sig_38_15 19891.0;
BA_ "frameSendMode" BO_ 328 2;
BA_ "sendPeriod" BO_ 328 10000;
BA_ "eventMinDistance" BO_ 328 50;
BA_ "crcStartValue" BO_ 328 178;
BA_ "initialValue" SG_ 328 sig_9_14 5.830000000000005E-6;
BA_ "initialValue" SG_ 328 sig_2_7 0.0047622776601683806;
BA_ "initialValue" SG_ 328 sig_1_2 2.0;
BA_ "initialValue" SG_ 328 sig_36_13 -341.0;
BA_ "initialValue" SG_ 328 sig_37_3 -1.0;
BA_ "frameSendMode" BO_ 844 2;
BA_ "sendPeriod" BO_ 844 1000;
BA_ "eventMinDistance" BO_ 844 100;
BA_ "crcStartValue" BO_ 844 9;
BA_ "initialValue" SG_ 844 sig_9_17 -2985.8776601683794;
BA_ "initialValue" SG_ 844 sig_5_11 -19.700000000000003;
BA_ "initialValue" SG_ 844 sig_6_2 1.0;
BA_ "initialValue" SG_ 844 sig_10_1 1.0;
BA_ "initialValue" SG_ 844 sig_42_9 0.002377223398316225;
BA_ "initialValue" SG_ 844 sig_43_4 1.0;
BA_ "initialValue" SG_ 844 sig_48_2 1.0;
BA_ "frameSendMode" BO_ 196 2;
BA_ "sendPeriod" BO_ 196 500;
BA_ "eventMinDistance" BO_ 196 500;
BA_ "crcStartValue" BO_ 196 246;
BA_ "initialValue" SG_ 196 sig_7_7 26.0;
BA_ "initialValue" SG_ 196 sig_21_2 2.0;
BA_ "initialValue" SG_ 196 sig_27_4 516.2277660168379;
BA_ "initialValue" SG_ 196 sig_19_2 -2.0;
BA_ "initialValue" SG_ 196 sig_35_15 -11145.776601683792;
BA_ "initialValue" SG_ 196 sig_38_2 3.0;
BA_ "initialValue" SG_ 196 sig_39_1 1.0;
BA_ "initialValue" SG_ 196 sig_48_4 7.0;
BA_ "crcStartValue" BO_ 870 50;
BA_ "initialValue" SG_ 870 sig_1_7 0.0636227766016838;
BA_ "initialValue" SG_ 870 sig_0_1 1.0;
BA_ "initialValue" SG_ 870 sig_17_20 -9481.47660168379;
BA_ "initialValue" SG_ 870 sig_37_3 -3.0;
BA_ "crcStartValue" BO_ 1492 229;
BA_ "initialValue" SG_ 1492 sig_7_7 2.4000000000000014E-4;
BA_ "initialValue" SG_ 1492 sig_32_7 37.0;
BA_ "initialValue" SG_ 1492 sig_16_10 382.22776601683796;
BA_ "initialValue" SG_ 1492 sig_17_7 1462.2776601683795;
BA_ "sendPeriod" BO_ 1401 5;
BA_ "crcStartValue" BO_ 1401 219;
BA_ "initialValue" SG_ 1401 sig_4_14 -0.03742776601683784;
BA_ "initialValue" SG_ 1401 sig_3_4 -7.0;
BA_ "initialValue" SG_ 1401 sig_23_5 -0.00406227766016838;
BA_ "initialValue" SG_ 1401 sig_18_1 1.0;
BA_ "initialValue" SG_ 1401 sig_33_15 2.8773000000000026E-4;
BA_ "sendPeriod" BO_ 1413 50;
BA_ "crcStartValue" BO_ 1413 161;
BA_ "initialValue" SG_ 1413 sig_10_10 2.522776601683775E-5;
BA_ "initialValue" SG_ 1413 sig_5_10 1022.0;
BA_ "initialValue" SG_ 1413 sig_11_1 1.0;
BA_ "initialValue" SG_ 1413 sig_16_9 4822.27766016838;
BA_ "initialValue" SG_ 1413 sig_47_6 1.500000000000001E-4;
BA_ "sendPeriod" BO_ 1185 500;
BA_ "crcStartValue" BO_ 1185 219;
BA_ "initialValue" SG_ 1185 sig_5_22 -1.3939306601683775E-4;
BA_ "initialValue" SG_ 1185 sig_30_6 -31.0;
BA_ "initialValue" SG_ 1185 sig_24_1 1.0;
BA_ "initialValue" SG_ 1185 sig_45_11 7.340000000000002;
BA_ "initialValue" SG_ 1185 sig_46_1 1.0;
BA_ "initialValue" SG_ 1185 sig_47_1 1.0;
BA_ "initialValue" SG_ 1185 sig_49_10 0.003457722339831624;
BA_ "sendPeriod" BO_ 322 25;
BA_ "crcStartValue" BO_ 322 142;
BA_ "initialValue" SG_ 322 sig_11_23 -7.589910000000011E-7;
BA_ "initialValue" SG_ 322 sig_7_8 -7.462277660168383E-5;
BA_ "initialValue" SG_ 322 sig_8_3 6.0;
BA_ "initialValue" SG_ 322 sig_36_2 2.0;
BA_ "initialValue" SG_ 322 sig_39_2 1.0;
BA_ "initialValue" SG_ 322 sig_55_16 0.0031957776601683795;
BA_ "sendPeriod" BO_ 1188 20;
BA_ "crcStartValue" BO_ 1188 40;
BA_ "initialValue" SG_ 1188 sig_39_6 30.0;
BA_ "initialValue" SG_ 1188 sig_3_16 214.02000000000004;
BA_ "initialValue" SG_ 1188 sig_18_11 0.01663000000000001;
BA_ "initialValue" SG_ 1188 sig_33_2 3.0;
BA_ "sendPeriod" BO_ 1340 5;
BA_ "crcStartValue" BO_ 1340 219;
BA_ "initialValue" SG_ 1340 sig_7_4 2.0;
BA_ "initialValue" SG_ 1340 sig_34_9 3832.2776601683795;
BA_ "initialValue" SG_ 1340 sig_27_9 7277.223398316208;
BA_ "initialValue" SG_ 1340 sig_19_5 -26.22776601683796;
BA_ "initialValue" SG_ 1340 sig_17_5 16.622776601683793;
BA_ "initialValue" SG_ 1340 sig_18_1 1.0;
BA_ "sendPeriod" BO_ 1151 20;
BA_ "crcStartValue" BO_ 1151 97;
BA_ "initialValue" SG_ 1151 sig_7_8 169.0;
BA_ "initialValue" SG_ 1151 sig_20_5 21.0;
BA_ "initialValue" SG_ 1151 sig_19_10 -339.0;
BA_ "initialValue" SG_ 1151 sig_25_1 1.0;
BA_ "initialValue" SG_ 1151 sig_45_6 7.0;
BA_ "initialValue" SG_ 1151 sig_32_6 -16.0;
BA_ "initialValue" SG_ 1151 sig_38_2 -2.0;
BA_ "initialValue" SG_ 1151 sig_54_7 5962.27766016838;
BA_ "sendPeriod" BO_ 2012 5;
BA_ "crcStartValue" BO_ 2012 230;
BA_ "initialValue" SG_ 2012 sig_7_8 178.3772233983162;
BA_ "initialValue" SG_ 2012 sig_39_5 190.0;
BA_ "initialValue" SG_ 2012 sig_20_10 -23.3;
BA_ "initialValue" SG_ 2012 sig_17_3 1.0;
BA_ "initialValue" SG_ 2012 sig_31_4 4.16227766016838E-6;
BA_ "initialValue" SG_ 2012 sig_41_13 4.9877223398316275E-6;
BA_ "sendPeriod" BO_ 1041 1000;
BA_ "crcStartValue" BO_ 1041 22;
BA_ "initialValue" SG_ 1041 sig_12_6 40.0;
BA_ "initialValue" SG_ 1041 sig_8_3 3.0;
BA_ "initialValue" SG_ 1041 sig_28_11 -29177.223398316208;
BA_ "initialValue" SG_ 1041 sig_23_6 7.0;
BA_ "initialValue" SG_ 1041 sig_24_4 -0.011622776601683787;
BA_ "initialValue" SG_ 1041 sig_47_6 -3.0000000000000018E-6;
BA_ "sendPeriod" BO_ 287 10000;
BA_ "crcStartValue" BO_ 287 199;
BA_ "initialValue" SG_ 287 sig_3_13 46.5827766016838;
BA_ "initialValue" SG_ 287 sig_7_4 13.0;
BA_ "initialValue" SG_ 287 sig_16_2 -1.0;
BA_ "initialValue" SG_ 287 sig_38_10 -80.22776601683796;
BA_ "initialValue" SG_ 287 sig_40_5 5.0;
BA_ "initialValue" SG_ 287 sig_54_6 7.862277660168382E-4;
BA_ "initialValue" SG_ 287 sig_55_1 1.0;
BA_ "sendPeriod" BO_ 138 5;
BA_ "crcStartValue" BO_ 138 60;
BA_ "initialValue" SG_ 138 sig_27_21 217058.5766016838;
BA_ "initialValue" SG_ 138 sig_8_1 1.0;
BA_ "sendPeriod" BO_ 1730 25;
BA_ "crcStartValue" BO_ 1730 14;
BA_ "initialValue" SG_ 1730 sig_16_28 -0.0010300591100000011;
BA_ "initialValue" SG_ 1730 sig_15_8 56377.22339831621;
BA_ "initialValue" SG_ 1730 sig_50_11 0.0026500000000000017;
BA_ "initialValue" SG_ 1730 sig_45_5 5000.0;
BA_ "sendPeriod" BO_ 937 5;
BA_ "crcStartValue" BO_ 937 93;
BA_ "initialValue" SG_ 937 sig_10_33 -7329.807831683778;
BA_ "initialValue" SG_ 937 sig_8_2 -1.0;
BA_ "initialValue" SG_ 937 sig_43_5 -9.622776601683784E-4;
BA_ "sendPeriod" BO_ 490 500;
BA_ "crcStartValue" BO_ 490 133;
BA_ "initialValue" SG_ 490 sig_28_10 -0.007532277660168382;
BA_ "initialValue" SG_ 490 sig_22_7 -62.0;
BA_ "initialValue" SG_ 490 sig_8_7 6.06227766016838;
BA_ "initialValue" SG_ 490 sig_15_1 1.0;
BA_ "initialValue" SG_ 490 sig_25_4 -81622.77660168378;
BA_ "initialValue" SG_ 490 sig_27_2 2.0;
BA_ "initialValue" SG_ 490 sig_46_16 5.239877660168381E-6;
BA_ "initialValue" SG_ 490 sig_62_5 7.0;
BA_ "initialValue" SG_ 490 sig_57_2 2.0;
BA_ "crcStartValue" BO_ 1827 16;
BA_ "initialValue" SG_ 1827 sig_8_9 -399.22776601683796;
BA_ "initialValue" SG_ 1827 sig_1_7 4.700000000000003E-5;
BA_ "initialValue" SG_ 1827 sig_9_7 0.9237722339831622;
BA_ "initialValue" SG_ 1827 sig_31_1 1.0;
BA_ "initialValue" SG_ 1827 sig_25_1 1.0;
BA_ "frameSendMode" BO_ 1819 2;
BA_ "sendPeriod" BO_ 1819 1000;
BA_ "eventMinDistance" BO_ 1819 500;
BA_ "crcStartValue" BO_ 1819 191;
BA_ "initialValue" SG_ 1819 sig_10_11 0.0011830000000000007;
BA_ "initialValue" SG_ 1819 sig_3_5 3.3622776601683794E-6;
BA_ "initialValue" SG_ 1819 sig_14_3 5.0;
BA_ "initialValue" SG_ 1819 sig_31_8 2.7622776601683796;
BA_ "initialValue" SG_ 1819 sig_42_11 0.06357722339831626;
BA_ "initialValue" SG_ 1819 sig_54_10 -1.8800000000000017E-6;
BA_ "initialValue" SG_ 1819 sig_53_1 1.0;
BA_ "sendPeriod" BO_ 46 1000;
BA_ "crcStartValue" BO_ 46 201;
BA_ "initialValue" SG_ 46 sig_1_14 0.062442776601683805;
BA_ "initialValue" SG_ 46 sig_0_2 -1.0;
BA_ "initialValue" SG_ 46 sig_29_10 6.310000000000004E-5;
BA_ "initialValue" SG_ 46 sig_24_5 6.0;
BA_ "initialValue" SG_ 46 sig_44_5 12.0;
BA_ "frameSendMode" BO_ 1255 2;
BA_ "sendPeriod" BO_ 1255 500;
BA_ "eventMinDistance" BO_ 1255 500;
BA_ "crcStartValue" BO_ 1255 81;
BA_ "initialValue" SG_ 1255 sig_29_10 -1.0922776601683774E-6;
BA_ "initialValue" SG_ 1255 sig_5_13 1072.027766016838;
BA_ "initialValue" SG_ 1255 sig_23_10 47.5;
BA_ "initialValue" SG_ 1255 sig_32_2 1.0;
BA_ "initialValue" SG_ 1255 sig_35_1 1.0;
BA_ "initialValue" SG_ 1255 sig_48_8 -0.8100000000000002;
BA_ "initialValue" SG_ 1255 sig_51_5 14000.0;
BA_ "initialValue" SG_ 1255 sig_49_2 1.0;
BA_ "sendPeriod" BO_ 1036 10000;
BA_ "crcStartValue" BO_ 1036 213;
BA_ "initialValue" SG_ 1036 sig_42_20 15231.0;
BA_ "initialValue" SG_ 1036 sig_8_20 6.362162339831632E-5;
BA_ "initialValue" SG_ 1036 sig_28_12 -1449.0;
BA_ "initialValue" SG_ 1036 sig_40_2 -1.0;
BA_ "sendPeriod" BO_ 1939 20;
BA_ "crcStartValue" BO_ 1939 18;
BA_ "initialValue" SG_ 1939 sig_30_19 0.043905300000000036;
BA_ "initialValue" SG_ 1939 sig_15_17 24021.223398316208;
BA_ "initialValue" SG_ 1939 sig_43_16 0.6240477660168382;
BA_ "initialValue" SG_ 1939 sig_58_2 3.0;
BA_ "initialValue" SG_ 1939 sig_57_2 1.0;
BA_ "sendPeriod" BO_ 922 20;
BA_ "crcStartValue" BO_ 922 249;
BA_ "initialValue" SG_ 922 sig_16_22 2.659033983162203;
BA_ "initialValue" SG_ 922 sig_4_9 4060.0;
BA_ "initialValue" SG_ 922 sig_0_4 13.0;
BA_ "initialValue" SG_ 922 sig_38_2 1.0;
BA_ "initialValue" SG_ 922 sig_49_6 -3.622776601683781E-4;
BA_ "sendPeriod" BO_ 759 50;
BA_ "crcStartValue" BO_ 759 51;
BA_ "initialValue" SG_ 759 sig_5_14 7.566722339831628E-4;
BA_ "initialValue" SG_ 759 sig_1_4 2.0;
BA_ "initialValue" SG_ 759 sig_0_1 1.0;
BA_ "initialValue" SG_ 759 sig_22_14 88.0;
BA_ "initialValue" SG_ 759 sig_21_3 6.0;
BA_ "initialValue" SG_ 759 sig_36_9 0.014600000000000007;
BA_ "sendPeriod" BO_ 88 50;
BA_ "crcStartValue" BO_ 88 149;
BA_ "initialValue" SG_ 88 sig_25_7 4.66227766016838E-6;
BA_ "initialValue" SG_ 88 sig_9_8 29.0;
BA_ "initialValue" SG_ 88 sig_15_6 -366.22776601683796;
BA_ "initialValue" SG_ 88 sig_16_2 2.0;
BA_ "initialValue" SG_ 88 sig_31_4 2.0;
BA_ "initialValue" SG_ 88 sig_47_8 -2.0;
BA_ "sendPeriod" BO_ 162 10000;
BA_ "crcStartValue" BO_ 162 120;
BA_ "initialValue" SG_ 162 sig_2_8 -2.5377223398316247E-6;
BA_ "initialValue" SG_ 162 sig_0_2 -1.0;
BA_ "initialValue" SG_ 162 sig_29_6 -30.0;
BA_ "initialValue" SG_ 162 sig_31_2 -1.0;
BA_ "sendPeriod" BO_ 659 10000;
BA_ "crcStartValue" BO_ 659 187;
BA_ "initialValue" SG_ 659 sig_7_19 -211687.0;
BA_ "initialValue" SG_ 659 sig_20_3 6.0;
BA_ "initialValue" SG_ 659 sig_33_2 1.0;
BA_ "frameSendMode" BO_ 495 2;
BA_ "sendPeriod" BO_ 495 100;
BA_ "eventMinDistance" BO_ 495 100;
BA_ "crcStartValue" BO_ 495 57;
BA_ "initialValue" SG_ 495 sig_1_15 2491.4776601683793;
BA_ "initialValue" SG_ 495 sig_26_29 59.52874270168381;
BA_ "initialValue" SG_ 495 sig_24_2 3.0;
BA_ "frameSendMode" BO_ 563 2;
BA_ "sendPeriod" BO_ 563 1000;
BA_ "eventMinDistance" BO_ 563 1000;
BA_ "crcStartValue" BO_ 563 14;
BA_ "initialValue" SG_ 563 sig_6_7 0.0011377223398316223;
BA_ "initialValue" SG_ 563 sig_7_1 1.0;
BA_ "initialValue" SG_ 563 sig_31_23 3.2428906601683796E-5;
BA_ "initialValue" SG_ 563 sig_23_8 65000.0;
BA_ "initialValue" SG_ 563 sig_40_1 1.0;
BA_ "frameSendMode" BO_ 1888 2;
BA_ "sendPeriod" BO_ 1888 50;
BA_ "eventMinDistance" BO_ 1888 50;
BA_ "crcStartValue" BO_ 1888 8;
BA_ "initialValue" SG_ 1888 sig_11_12 3.6332776601683796;
BA_ "initialValue" SG_ 1888 sig_0_10 0.008192277660168383;
BA_ "initialValue" SG_ 1888 sig_10_1 1.0;
BA_ "initialValue" SG_ 1888 sig_33_17 654.667766016838;
BA_ "initialValue" SG_ 1888 sig_32_1 1.0;
BA_ "initialValue" SG_ 1888 sig_53_2 -2.0;
BA_ "initialValue" SG_ 1888 sig_50_3 5.0;
BA_ "sendPeriod" BO_ 981 1000;
BA_ "crcStartValue" BO_ 981 174;
BA_ "initialValue" SG_ 981 sig_9_10 3540.0;
BA_ "initialValue" SG_ 981 sig_6_13 892.0;
BA_ "initialValue" SG_ 981 sig_7_1 1.0;
BA_ "initialValue" SG_ 981 sig_31_8 66.0;
BA_ "initialValue" SG_ 981 sig_47_8 0.03262277660168379;
BA_ "sendPeriod" BO_ 708 25;
BA_ "crcStartValue" BO_ 708 207;
BA_ "initialValue" SG_ 708 sig_36_3 1.0;
BA_ "initialValue" SG_ 708 sig_0_9 -13122.776601683792;
BA_ "initialValue" SG_ 708 sig_22_9 1547.7223398316205;
BA_ "initialValue" SG_ 708 sig_15_5 14.0;
BA_ "initialValue" SG_ 708 sig_9_2 -1.0;
BA_ "initialValue" SG_ 708 sig_32_3 2.0;
BA_ "initialValue" SG_ 708 sig_35_1 1.0;
BA_ "initialValue" SG_ 708 sig_42_10 -2.7500000000000025E-6;
BA_ "initialValue" SG_ 708 sig_47_3 -4.0;
BA_ "initialValue" SG_ 708 sig_44_2 3.0;
BA_ "frameSendMode" BO_ 1382 2;
BA_ "sendPeriod" BO_ 1382 500;
BA_ "eventMinDistance" BO_ 1382 50;
BA_ "crcStartValue" BO_ 1382 197;
BA_ "initialValue" SG_ 1382 sig_17_15 3.2028776601683795E-4;
BA_ "initialValue" SG_ 1382 sig_8_9 -204.0;
BA_ "frameSendMode" BO_ 1345 2;
BA_ "sendPeriod" BO_ 1345 1000;
BA_ "eventMinDistance" BO_ 1345 1000;
BA_ "crcStartValue" BO_ 1345 157;
BA_ "initialValue" SG_ 1345 sig_6_2 1.0;
BA_ "initialValue" SG_ 1345 sig_0_6 10.0;
BA_ "initialValue" SG_ 1345 sig_19_23 0.2438005660168379;
BA_ "initialValue" SG_ 1345 sig_10_8 60.0;
BA_ "initialValue" SG_ 1345 sig_18_1 1.0;
BA_ "initialValue" SG_ 1345 sig_42_6 17.0;
BA_ "sendPeriod" BO_ 1618 20;
BA_ "crcStartValue" BO_ 1618 211;
BA_ "initialValue" SG_ 1618 sig_3_12 -1981.0;
BA_ "initialValue" SG_ 1618 sig_15_1 1.0;
BA_ "initialValue" SG_ 1618 sig_25_6 -12622.776601683792;
BA_ "frameSendMode" BO_ 1956 2;
BA_ "sendPeriod" BO_ 1956 50;
BA_ "eventMinDistance" BO_ 1956 50;
BA_ "crcStartValue" BO_ 1956 116;
BA_ "initialValue" SG_ 1956 sig_3_9 -203.0;
BA_ "initialValue" SG_ 1956 sig_0_3 6.0;
BA_ "initialValue" SG_ 1956 sig_2_2 1.0;
BA_ "initialValue" SG_ 1956 sig_13_2 -1.0;
BA_ "initialValue" SG_ 1956 sig_16_6 0.36622776601683793;
BA_ "initialValue" SG_ 1956 sig_22_2 -1.0;
BA_ "initialValue" SG_ 1956 sig_39_8 3.622776601683775E-5;
BA_ "frameSendMode" BO_ 497 2;
BA_ "sendPeriod" BO_ 497 10000;
BA_ "eventMinDistance" BO_ 497 100;
BA_ "crcStartValue" BO_ 497 3;
BA_ "initialValue" SG_ 497 sig_5_5 2.2622776601683785E-6;
BA_ "initialValue" SG_ 497 sig_0_3 2.0;
BA_ "initialValue" SG_ 497 sig_4_2 -1.0;
BA_ "initialValue" SG_ 497 sig_23_13 283.827766016838;
BA_ "initialValue" SG_ 497 sig_15_6 47.0;
BA_ "initialValue" SG_ 497 sig_20_2 1.0;
BA_ "initialValue" SG_ 497 sig_16_3 4.0;
BA_ "initialValue" SG_ 497 sig_22_2 1.0;
BA_ "initialValue" SG_ 497 sig_36_11 -860.0;
BA_ "sendPeriod" BO_ 463 20;
BA_ "crcStartValue" BO_ 463 219;
BA_ "initialValue" SG_ 463 sig_3_5 5.0;
BA_ "initialValue" SG_ 463 sig_23_13 0.14700000000000005;
BA_ "initialValue" SG_ 463 sig_25_2 3.0;
BA_ "frameSendMode" BO_ 954 2;
BA_ "sendPeriod" BO_ 954 10000;
BA_ "eventMinDistance" BO_ 954 500;
BA_ "crcStartValue" BO_ 954 164;
BA_ "initialValue" SG_ 954 sig_0_7 48.0;
BA_ "initialValue" SG_ 954 sig_7_1 1.0;
BA_ "initialValue" SG_ 954 sig_29_9 150.0;
BA_ "initialValue" SG_ 954 sig_23_8 127.3772233983162;
BA_ "initialValue" SG_ 954 sig_24_5 -9.0;
BA_ "initialValue" SG_ 954 sig_39_8 566.2277660168379;
BA_ "initialValue" SG_ 954 sig_59_4 0.0012162277660168383;
BA_ "initialValue" SG_ 954 sig_54_11 182.22776601683796;
BA_ "initialValue" SG_ 954 sig_55_1 1.0;
BA_ "crcStartValue" BO_ 1514 122;
BA_ "initialValue" SG_ 1514 sig_8_20 0.8227877660168383;
BA_ "initialValue" SG_ 1514 sig_2_10 56.5;
BA_ "initialValue" SG_ 1514 sig_7_5 -1.2000000000000007E-4;
BA_ "initialValue" SG_ 1514 sig_34_7 -0.5062277660168379;
BA_ "initialValue" SG_ 1514 sig_42_3 1.0;
BA_ "initialValue" SG_ 1514 sig_63_7 -26.0;
BA_ "frameSendMode" BO_ 92 2;
BA_ "sendPeriod" BO_ 92 500;
BA_ "eventMinDistance" BO_ 92 50;
BA_ "crcStartValue" BO_ 92 213;
BA_ "initialValue" SG_ 92 sig_11_10 1550.0;
BA_ "initialValue" SG_ 92 sig_6_7 -31.0;
BA_ "initialValue" SG_ 92 sig_7_4 13.0;
BA_ "initialValue" SG_ 92 sig_21_11 11847.72233983162;
BA_ "initialValue" SG_ 92 sig_53_12 3556.0;
BA_ "initialValue" SG_ 92 sig_40_8 60.0;
BA_ "crcStartValue" BO_ 1350 95;
BA_ "initialValue" SG_ 1350 sig_12_10 5070.0;
BA_ "initialValue" SG_ 1350 sig_1_10 1.520000000000001E-4;
BA_ "initialValue" SG_ 1350 sig_32_27 -5.372154060168382E-4;
BA_ "initialValue" SG_ 1350 sig_59_4 0.5;
BA_ "crcStartValue" BO_ 1126 11;
BA_ "initialValue" SG_ 1126 sig_14_18 0.005469700000000004;
BA_ "initialValue" SG_ 1126 sig_15_1 1.0;
BA_ "initialValue" SG_ 1126 sig_28_5 33622.77660168379;
BA_ "initialValue" SG_ 1126 sig_46_14 -2137.0;
BA_ "sendPeriod" BO_ 1347 25;
BA_ "crcStartValue" BO_ 1347 179;
BA_ "initialValue" SG_ 1347 sig_17_8 -29.0;
BA_ "initialValue" SG_ 1347 sig_13_11 1507.0;
BA_ "initialValue" SG_ 1347 sig_15_2 3.0;
BA_ "initialValue" SG_ 1347 sig_24_2 3.0;
BA_ "initialValue" SG_ 1347 sig_37_9 -0.0012122776601683782;
BA_ "initialValue" SG_ 1347 sig_32_3 2.0;
BA_ "initialValue" SG_ 1347 sig_36_2 2.0;
BA_ "sendPeriod" BO_ 31 1000;
BA_ "crcStartValue" BO_ 31 66;
BA_ "initialValue" SG_ 31 sig_15_12 1459.0;
BA_ "initialValue" SG_ 31 sig_19_4 9.162277660168384E-5;
BA_ "sendPeriod" BO_ 1694 25;
BA_ "crcStartValue" BO_ 1694 172;
BA_ "initialValue" SG_ 1694 sig_24_18 24.52122339831622;
BA_ "initialValue" SG_ 1694 sig_22_7 0.026000000000000006;
BA_ "initialValue" SG_ 1694 sig_23_1 1.0;
BA_ "initialValue" SG_ 1694 sig_45_4 12.0;
BA_ "initialValue" SG_ 1694 sig_47_2 -1.0;
BA_ "sendPeriod" BO_ 725 10000;
BA_ "crcStartValue" BO_ 725 96;
BA_ "initialValue" SG_ 725 sig_6_15 0.0033508776601683795;
BA_ "initialValue" SG_ 725 sig_1_2 -2.0;
BA_ "initialValue" SG_ 725 sig_23_3 -2.0;
BA_ "initialValue" SG_ 725 sig_35_14 2121.0;
BA_ "initialValue" SG_ 725 sig_36_3 1.0;
BA_ "initialValue" SG_ 725 sig_53_6 -26622.776601683792;
BA_ "frameSendMode" BO_ 729 2;
BA_ "sendPeriod" BO_ 729 1000;
BA_ "eventMinDistance" BO_ 729 50;
BA_ "crcStartValue" BO_ 729 5;
BA_ "initialValue" SG_ 729 sig_5_17 127364.0;
BA_ "initialValue" SG_ 729 sig_7_2 1.0;
BA_ "initialValue" SG_ 729 sig_17_4 60000.0;
BA_ "initialValue" SG_ 729 sig_35_12 1.3920000000000012E-6;
BA_ "initialValue" SG_ 729 sig_32_3 5.0;
BA_ "sendPeriod" BO_ 429 1000;
BA_ "crcStartValue" BO_ 429 164;
BA_ "initialValue" SG_ 429 sig_4_12 -1833.2776601683795;
BA_ "initialValue" SG_ 429 sig_22_10 229.0;
BA_ "initialValue" SG_ 429 sig_16_1 1.0;
BA_ "initialValue" SG_ 429 sig_49_12 -1282.0;
BA_ "initialValue" SG_ 429 sig_40_9 226.0;
BA_ "initialValue" SG_ 429 sig_61_2 -2.0;
BA_ "frameSendMode" BO_ 633 2;
BA_ "sendPeriod" BO_ 633 10000;
BA_ "eventMinDistance" BO_ 633 100;
BA_ "crcStartValue" BO_ 633 172;
BA_ "initialValue" SG_ 633 sig_0_8 147.0;
BA_ "frameSendMode" BO_ 2045 2;
BA_ "sendPeriod" BO_ 2045 1000;
BA_ "eventMinDistance" BO_ 2045 500;
BA_ "crcStartValue" BO_ 2045 150;
BA_ "initialValue" SG_ 2045 sig_0_8 430.0;
BA_ "initialValue" SG_ 2045 sig_21_16 217.41223398316214;
BA_ "initialValue" SG_ 2045 sig_23_2 2.0;
BA_ "initialValue" SG_ 2045 sig_37_6 9.0;
BA_ "crcStartValue" BO_ 1005 66;
BA_ "initialValue" SG_ 1005 sig_19_16 0.10142233983162185;
BA_ "initialValue" SG_ 1005 sig_8_8 1.3200000000000009E-5;
BA_ "initialValue" SG_ 1005 sig_20_3 5.0;
BA_ "initialValue" SG_ 1005 sig_23_1 1.0;
BA_ "initialValue" SG_ 1005 sig_32_4 1.0;
BA_ "initialValue" SG_ 1005 sig_40_8 37.0;
BA_ "frameSendMode" BO_ 1794 2;
BA_ "sendPeriod" BO_ 1794 100;
BA_ "eventMinDistance" BO_ 1794 50;
BA_ "crcStartValue" BO_ 1794 143;
BA_ "initialValue" SG_ 1794 sig_6_18 0.01854617766016839;
BA_ "initialValue" SG_ 1794 sig_19_4 -2837.7223398316205;
BA_ "initialValue" SG_ 1794 sig_52_13 4054.0;
BA_ "initialValue" SG_ 1794 sig_47_11 62.0;
BA_ "initialValue" SG_ 1794 sig_39_8 -27.0;
BA_ "sendPeriod" BO_ 1901 1000;
BA_ "crcStartValue" BO_ 1901 150;
BA_ "initialValue" SG_ 1901 sig_15_6 56.0;
BA_ "initialValue" SG_ 1901 sig_0_10 3470.0;
BA_ "initialValue" SG_ 1901 sig_27_5 8.0;
BA_ "initialValue" SG_ 1901 sig_28_4 -2.162277660168379E-5;
BA_ "initialValue" SG_ 1901 sig_38_1 1.0;
BA_ "initialValue" SG_ 1901 sig_43_11 -6390.0;
BA_ "initialValue" SG_ 1901 sig_48_1 1.0;
BA_ "sendPeriod" BO_ 1010 50;
BA_ "crcStartValue" BO_ 1010 135;
BA_ "initialValue" SG_ 1010 sig_6_19 982.412339831621;
BA_ "initialValue" SG_ 1010 sig_7_1 1.0;
BA_ "initialValue" SG_ 1010 sig_24_8 6.9377223398316215;
BA_ "sendPeriod" BO_ 381 1000;
BA_ "crcStartValue" BO_ 381 94;
BA_ "initialValue" SG_ 381 sig_4_7 -4100.0;
BA_ "initialValue" SG_ 381 sig_0_3 6.0;
BA_ "initialValue" SG_ 381 sig_3_1 1.0;
BA_ "initialValue" SG_ 381 sig_11_5 8.0;
BA_ "initialValue" SG_ 381 sig_31_5 2.7622776601683796;
BA_ "initialValue" SG_ 381 sig_38_5 21.0;
BA_ "initialValue" SG_ 381 sig_48_6 7.000000000000005E-7;
BA_ "initialValue" SG_ 381 sig_55_2 1.0;
BA_ "initialValue" SG_ 381 sig_63_8 7.4377223398316294E-6;
BA_ "sendPeriod" BO_ 796 25;
BA_ "crcStartValue" BO_ 796 129;
BA_ "initialValue" SG_ 796 sig_10_18 1.6481177660168387;
BA_ "initialValue" SG_ 796 sig_0_8 1.0000000000000007E-7;
BA_ "initialValue" SG_ 796 sig_13_3 2.0;
BA_ "initialValue" SG_ 796 sig_24_1 1.0;
BA_ "initialValue" SG_ 796 sig_39_7 -47.0;
BA_ "initialValue" SG_ 796 sig_32_1 1.0;
BA_ "sendPeriod" BO_ 260 50;
BA_ "crcStartValue" BO_ 260 50;
BA_ "initialValue" SG_ 260 sig_3_14 -6465.0;
BA_ "initialValue" SG_ 260 sig_2_3 4.0;
BA_ "initialValue" SG_ 260 sig_21_8 123.0;
BA_ "initialValue" SG_ 260 sig_17_4 -4.83772233983162;
BA_ "initialValue" SG_ 260 sig_29_11 2.2922776601683788E-4;
BA_ "initialValue" SG_ 260 sig_49_7 78.0;
BA_ "frameSendMode" BO_ 1337 2;
BA_ "sendPeriod" BO_ 1337 1000;
BA_ "eventMinDistance" BO_ 1337 1000;
BA_ "crcStartValue" BO_ 1337 62;
BA_ "initialValue" SG_ 1337 sig_2_16 5.032500000000006E-6;
BA_ "initialValue" SG_ 1337 sig_17_15 5143.0;
BA_ "initialValue" SG_ 1337 sig_43_8 8.700000000000005E-4;
BA_ "initialValue" SG_ 1337 sig_34_7 -2.1377223398316237E-4;
BA_ "initialValue" SG_ 1337 sig_51_4 14.0;
BA_ "sendPeriod" BO_ 1652 20;
BA_ "crcStartValue" BO_ 1652 34;
BA_ "initialValue" SG_ 1652 sig_2_3 -2.0;
BA_ "initialValue" SG_ 1652 sig_7_3 2.0;
BA_ "initialValue" SG_ 1652 sig_1_2 1.0;
BA_ "initialValue" SG_ 1652 sig_38_12 2985.0;
BA_ "initialValue" SG_ 1652 sig_22_13 0.09454277660168382;
BA_ "initialValue" SG_ 1652 sig_23_3 6.0;
BA_ "initialValue" SG_ 1652 sig_48_8 -30.0;
BA_ "frameSendMode" BO_ 1442 2;
BA_ "sendPeriod" BO_ 1442 1000;
BA_ "eventMinDistance" BO_ 1442 500;
BA_ "crcStartValue" BO_ 1442 149;
BA_ "initialValue" SG_ 1442 sig_14_5 -1.9622776601683788E-5;
BA_ "initialValue" SG_ 1442 sig_15_1 1.0;
BA_ "initialValue" SG_ 1442 sig_9_2 1.0;
